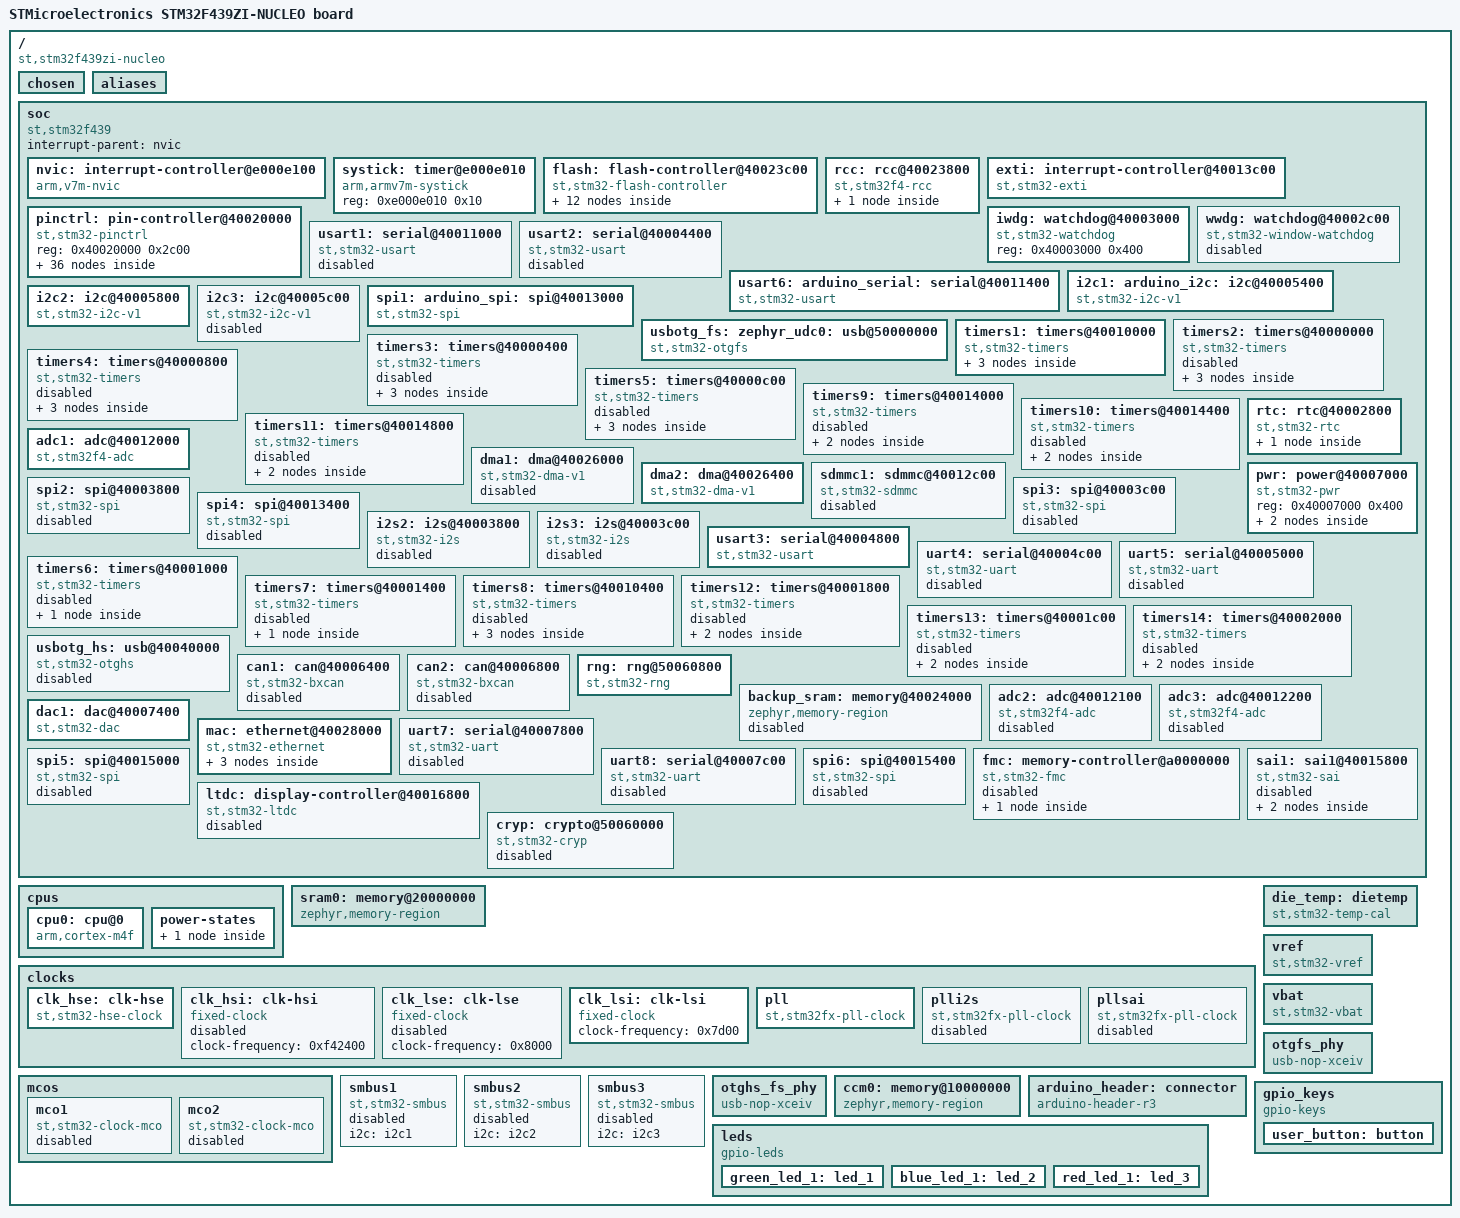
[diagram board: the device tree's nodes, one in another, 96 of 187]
/dts-v1/;

/* node '/' defined in zephyr/dts/common/skeleton.dtsi:9 */
/ {
	#address-cells = < 0x1 >;                              /* in zephyr/dts/common/skeleton.dtsi:10 */
	#size-cells = < 0x1 >;                                 /* in zephyr/dts/common/skeleton.dtsi:11 */
	model = "STMicroelectronics STM32F439ZI-NUCLEO board"; /* in zephyr/boards/st/nucleo_f439zi/nucleo_f439zi.dts:14 */
	compatible = "st,stm32f439zi-nucleo";                  /* in zephyr/boards/st/nucleo_f439zi/nucleo_f439zi.dts:15 */

	/* node '/chosen' defined in zephyr/dts/common/skeleton.dtsi:13 */
	chosen {
		zephyr,flash-controller = &flash;         /* in zephyr/dts/arm/st/f4/stm32f4.dtsi:26 */
		zephyr,system-timer-companion = &rtc;     /* in zephyr/dts/arm/st/f4/stm32f4.dtsi:27 */
		zephyr,entropy = &rng;                    /* in zephyr/dts/arm/st/f4/stm32f405.dtsi:13 */
		zephyr,sram = &sram0;                     /* in zephyr/boards/st/nucleo_f439zi/nucleo_f439zi.dts:20 */
		zephyr,flash = &flash0;                   /* in zephyr/boards/st/nucleo_f439zi/nucleo_f439zi.dts:21 */
		zephyr,dtcm = &ccm0;                      /* in zephyr/boards/st/nucleo_f439zi/nucleo_f439zi.dts:22 */
		zephyr,code-partition = &slot0_partition; /* in zephyr/boards/st/nucleo_f439zi/nucleo_f439zi.dts:23 */
		zephyr,shell-uart = &usart3;              /* in ../../../../development/germany/sm3/research/can_t1s_latency_bench/host-tools/demo/terminal_config/build/zephyr/boards/nucleo_f439zi.overlay:3 */
		zephyr,console = &usart3;                 /* in ../../../../development/germany/sm3/research/can_t1s_latency_bench/host-tools/demo/terminal_config/build/zephyr/boards/nucleo_f439zi.overlay:4 */
	};

	/* node '/aliases' defined in zephyr/dts/common/skeleton.dtsi:15 */
	aliases {
		led0 = &green_led_1;   /* in zephyr/boards/st/nucleo_f439zi/nucleo_f439zi.dts:56 */
		led1 = &blue_led_1;    /* in zephyr/boards/st/nucleo_f439zi/nucleo_f439zi.dts:57 */
		led2 = &red_led_1;     /* in zephyr/boards/st/nucleo_f439zi/nucleo_f439zi.dts:58 */
		sw0 = &user_button;    /* in zephyr/boards/st/nucleo_f439zi/nucleo_f439zi.dts:59 */
		watchdog0 = &iwdg;     /* in zephyr/boards/st/nucleo_f439zi/nucleo_f439zi.dts:60 */
		die-temp0 = &die_temp; /* in zephyr/boards/st/nucleo_f439zi/nucleo_f439zi.dts:61 */
		volt-sensor0 = &vref;  /* in zephyr/boards/st/nucleo_f439zi/nucleo_f439zi.dts:62 */
		volt-sensor1 = &vbat;  /* in zephyr/boards/st/nucleo_f439zi/nucleo_f439zi.dts:63 */
	};

	/* node '/soc' defined in zephyr/dts/arm/armv7-m.dtsi:6 */
	soc {
		#address-cells = < 0x1 >;     /* in zephyr/dts/arm/armv7-m.dtsi:7 */
		#size-cells = < 0x1 >;        /* in zephyr/dts/arm/armv7-m.dtsi:8 */
		interrupt-parent = < &nvic >; /* in zephyr/dts/arm/armv7-m.dtsi:10 */
		ranges;                       /* in zephyr/dts/arm/armv7-m.dtsi:11 */
		compatible = "st,stm32f439",
		             "st,stm32f4",
		             "simple-bus";    /* in zephyr/dts/arm/st/f4/stm32f439.dtsi:11 */

		/* node '/soc/interrupt-controller@e000e100' defined in zephyr/dts/arm/armv7-m.dtsi:13 */
		nvic: interrupt-controller@e000e100 {
			#address-cells = < 0x1 >;            /* in zephyr/dts/arm/armv7-m.dtsi:14 */
			compatible = "arm,v7m-nvic";         /* in zephyr/dts/arm/armv7-m.dtsi:15 */
			reg = < 0xe000e100 0xc00 >;          /* in zephyr/dts/arm/armv7-m.dtsi:16 */
			interrupt-controller;                /* in zephyr/dts/arm/armv7-m.dtsi:17 */
			#interrupt-cells = < 0x2 >;          /* in zephyr/dts/arm/armv7-m.dtsi:18 */
			arm,num-irq-priority-bits = < 0x4 >; /* in zephyr/dts/arm/st/f4/stm32f4.dtsi:733 */
			phandle = < 0x1 >;                   /* in zephyr/dts/arm/armv7-m.dtsi:10 */
		};

		/* node '/soc/timer@e000e010' defined in zephyr/dts/arm/armv7-m.dtsi:21 */
		systick: timer@e000e010 {
			compatible = "arm,armv7m-systick"; /* in zephyr/dts/arm/armv7-m.dtsi:22 */
			reg = < 0xe000e010 0x10 >;         /* in zephyr/dts/arm/armv7-m.dtsi:23 */
		};

		/* node '/soc/flash-controller@40023c00' defined in zephyr/dts/arm/st/f4/stm32f4.dtsi:112 */
		flash: flash-controller@40023c00 {
			compatible = "st,stm32-flash-controller",
			             "st,stm32f4-flash-controller"; /* in zephyr/dts/arm/st/f4/stm32f4.dtsi:113 */
			reg = < 0x40023c00 0x400 >;                 /* in zephyr/dts/arm/st/f4/stm32f4.dtsi:114 */
			interrupts = < 0x4 0x0 >;                   /* in zephyr/dts/arm/st/f4/stm32f4.dtsi:115 */
			#address-cells = < 0x1 >;                   /* in zephyr/dts/arm/st/f4/stm32f4.dtsi:117 */
			#size-cells = < 0x1 >;                      /* in zephyr/dts/arm/st/f4/stm32f4.dtsi:118 */
			ranges;                                     /* in zephyr/dts/arm/st/f4/stm32f4.dtsi:119 */

			/* node '/soc/flash-controller@40023c00/flash@8000000' defined in zephyr/dts/arm/st/f4/stm32f4.dtsi:121 */
			flash0: flash@8000000 {
				compatible = "st,stm32f4-nv-flash",
				             "st,stm32-nv-flash",
				             "soc-nv-flash";         /* in zephyr/dts/arm/st/f4/stm32f4.dtsi:122 */
				#address-cells = < 0x1 >;            /* in zephyr/dts/arm/st/f4/stm32f4.dtsi:124 */
				#size-cells = < 0x1 >;               /* in zephyr/dts/arm/st/f4/stm32f4.dtsi:125 */
				write-block-size = < 0x1 >;          /* in zephyr/dts/arm/st/f4/stm32f4.dtsi:126 */
				max-erase-time = < 0xfa0 >;          /* in zephyr/dts/arm/st/f4/stm32f4.dtsi:128 */
				reg = < 0x8000000 0x200000 >;        /* in zephyr/dts/arm/st/f4/stm32f439Xi.dtsi:23 */
				ranges = < 0x0 0x8000000 0x200000 >; /* in zephyr/dts/arm/st/f4/stm32f439Xi.dtsi:24 */

				/* node '/soc/flash-controller@40023c00/flash@8000000/partitions' defined in zephyr/boards/st/nucleo_f439zi/nucleo_f439zi.dts:212 */
				partitions {
					#address-cells = < 0x1 >; /* in zephyr/boards/st/nucleo_f439zi/nucleo_f439zi.dts:213 */
					#size-cells = < 0x1 >;    /* in zephyr/boards/st/nucleo_f439zi/nucleo_f439zi.dts:214 */
					ranges;                   /* in zephyr/boards/st/nucleo_f439zi/nucleo_f439zi.dts:215 */

					/* node '/soc/flash-controller@40023c00/flash@8000000/partitions/partition@0' defined in zephyr/boards/st/nucleo_f439zi/nucleo_f439zi.dts:218 */
					boot_partition: partition@0 {
						compatible = "zephyr,mapped-partition"; /* in zephyr/boards/st/nucleo_f439zi/nucleo_f439zi.dts:219 */
						label = "mcuboot";                      /* in zephyr/boards/st/nucleo_f439zi/nucleo_f439zi.dts:220 */
						reg = < 0x0 0x8000 >;                   /* in zephyr/boards/st/nucleo_f439zi/nucleo_f439zi.dts:221 */
						read-only;                              /* in zephyr/boards/st/nucleo_f439zi/nucleo_f439zi.dts:222 */
					};

					/* node '/soc/flash-controller@40023c00/flash@8000000/partitions/partition@20000' defined in zephyr/boards/st/nucleo_f439zi/nucleo_f439zi.dts:248 */
					slot0_partition: partition@20000 {
						compatible = "zephyr,mapped-partition"; /* in zephyr/boards/st/nucleo_f439zi/nucleo_f439zi.dts:249 */
						label = "image-0";                      /* in zephyr/boards/st/nucleo_f439zi/nucleo_f439zi.dts:250 */
						reg = < 0x20000 0xe0000 >;              /* in zephyr/boards/st/nucleo_f439zi/nucleo_f439zi.dts:251 */
					};

					/* node '/soc/flash-controller@40023c00/flash@8000000/partitions/partition@120000' defined in zephyr/boards/st/nucleo_f439zi/nucleo_f439zi.dts:264 */
					slot1_partition: partition@120000 {
						compatible = "zephyr,mapped-partition"; /* in zephyr/boards/st/nucleo_f439zi/nucleo_f439zi.dts:265 */
						label = "image-1";                      /* in zephyr/boards/st/nucleo_f439zi/nucleo_f439zi.dts:266 */
						reg = < 0x120000 0xc0000 >;             /* in zephyr/boards/st/nucleo_f439zi/nucleo_f439zi.dts:267 */
					};

					/* node '/soc/flash-controller@40023c00/flash@8000000/partitions/partition@8000' defined in ../../../../development/germany/sm3/research/can_t1s_latency_bench/host-tools/demo/terminal_config/build/zephyr/boards/nucleo_f439zi.overlay:16 */
					storage_partition: partition@8000 {
						compatible = "zephyr,mapped-partition"; /* in ../../../../development/germany/sm3/research/can_t1s_latency_bench/host-tools/demo/terminal_config/build/zephyr/boards/nucleo_f439zi.overlay:17 */
						label = "storage";                      /* in ../../../../development/germany/sm3/research/can_t1s_latency_bench/host-tools/demo/terminal_config/build/zephyr/boards/nucleo_f439zi.overlay:18 */
						reg = < 0x8000 0x8000 >;                /* in ../../../../development/germany/sm3/research/can_t1s_latency_bench/host-tools/demo/terminal_config/build/zephyr/boards/nucleo_f439zi.overlay:19 */
					};
				};
			};

			/* node '/soc/flash-controller@40023c00/flash@1fff7800' defined in zephyr/dts/arm/st/f4/stm32f4.dtsi:131 */
			st_nvm_user_otp: flash@1fff7800 {
				compatible = "st,stm32-nvm-otp"; /* in zephyr/dts/arm/st/f4/stm32f4.dtsi:132 */
				reg = < 0x1fff7800 0x200 >;      /* in zephyr/dts/arm/st/f4/stm32f4.dtsi:133 */
				status = "disabled";             /* in zephyr/dts/arm/st/f4/stm32f4.dtsi:134 */
			};

			/* node '/soc/flash-controller@40023c00/flash@1fff7a00' defined in zephyr/dts/arm/st/f4/stm32f4.dtsi:148 */
			flash@1fff7a00 {
				compatible = "st,stm32-nvm-otp"; /* in zephyr/dts/arm/st/f4/stm32f4.dtsi:149 */
				reg = < 0x1fff7a00 0x100 >;      /* in zephyr/dts/arm/st/f4/stm32f4.dtsi:150 */

				/* node '/soc/flash-controller@40023c00/flash@1fff7a00/nvmem-layout' defined in zephyr/dts/arm/st/f4/stm32f4.dtsi:152 */
				nvmem-layout {
					compatible = "fixed-layout"; /* in zephyr/dts/arm/st/f4/stm32f4.dtsi:153 */
					#address-cells = < 0x1 >;    /* in zephyr/dts/arm/st/f4/stm32f4.dtsi:154 */
					#size-cells = < 0x1 >;       /* in zephyr/dts/arm/st/f4/stm32f4.dtsi:155 */

					/* node '/soc/flash-controller@40023c00/flash@1fff7a00/nvmem-layout/vrefint@2a' defined in zephyr/dts/arm/st/f4/stm32f4.dtsi:157 */
					vrefint_otp: vrefint@2a {
						reg = < 0x2a 0x2 >;          /* in zephyr/dts/arm/st/f4/stm32f4.dtsi:158 */
						#nvmem-cell-cells = < 0x0 >; /* in zephyr/dts/arm/st/f4/stm32f4.dtsi:159 */
						read-only;                   /* in zephyr/dts/arm/st/f4/stm32f4.dtsi:160 */
						phandle = < 0x2b >;          /* in zephyr/dts/arm/st/f4/stm32f4.dtsi:689 */
					};

					/* node '/soc/flash-controller@40023c00/flash@1fff7a00/nvmem-layout/ts-cal1@2c' defined in zephyr/dts/arm/st/f4/stm32f4.dtsi:163 */
					ts_cal1_otp: ts-cal1@2c {
						reg = < 0x2c 0x2 >;          /* in zephyr/dts/arm/st/f4/stm32f4.dtsi:164 */
						#nvmem-cell-cells = < 0x0 >; /* in zephyr/dts/arm/st/f4/stm32f4.dtsi:165 */
						read-only;                   /* in zephyr/dts/arm/st/f4/stm32f4.dtsi:166 */
						phandle = < 0x28 >;          /* in zephyr/dts/arm/st/f4/stm32f4.dtsi:678 */
					};

					/* node '/soc/flash-controller@40023c00/flash@1fff7a00/nvmem-layout/ts-cal2@2e' defined in zephyr/dts/arm/st/f4/stm32f4.dtsi:169 */
					ts_cal2_otp: ts-cal2@2e {
						reg = < 0x2e 0x2 >;          /* in zephyr/dts/arm/st/f4/stm32f4.dtsi:170 */
						#nvmem-cell-cells = < 0x0 >; /* in zephyr/dts/arm/st/f4/stm32f4.dtsi:171 */
						read-only;                   /* in zephyr/dts/arm/st/f4/stm32f4.dtsi:172 */
						phandle = < 0x29 >;          /* in zephyr/dts/arm/st/f4/stm32f4.dtsi:678 */
					};
				};
			};
		};

		/* node '/soc/rcc@40023800' defined in zephyr/dts/arm/st/f4/stm32f4.dtsi:178 */
		rcc: rcc@40023800 {
			#clock-cells = < 0x2 >;          /* in zephyr/dts/arm/st/f4/stm32f4.dtsi:180 */
			reg = < 0x40023800 0x400 >;      /* in zephyr/dts/arm/st/f4/stm32f4.dtsi:181 */
			compatible = "st,stm32f4-rcc";   /* in zephyr/dts/arm/st/f4/stm32f427.dtsi:25 */
			clocks = < &pll >;               /* in zephyr/boards/st/nucleo_f439zi/nucleo_f439zi.dts:87 */
			clock-frequency = < 0xa037a00 >; /* in zephyr/boards/st/nucleo_f439zi/nucleo_f439zi.dts:88 */
			ahb-prescaler = < 0x1 >;         /* in zephyr/boards/st/nucleo_f439zi/nucleo_f439zi.dts:89 */
			apb1-prescaler = < 0x4 >;        /* in zephyr/boards/st/nucleo_f439zi/nucleo_f439zi.dts:90 */
			apb2-prescaler = < 0x2 >;        /* in zephyr/boards/st/nucleo_f439zi/nucleo_f439zi.dts:91 */
			phandle = < 0x3 >;               /* in zephyr/dts/arm/st/f4/stm32f4.dtsi:195 */

			/* node '/soc/rcc@40023800/reset-controller' defined in zephyr/dts/arm/st/f4/stm32f4.dtsi:183 */
			rctl: reset-controller {
				compatible = "st,stm32-rcc-rctl"; /* in zephyr/dts/arm/st/f4/stm32f4.dtsi:184 */
				#reset-cells = < 0x1 >;           /* in zephyr/dts/arm/st/f4/stm32f4.dtsi:185 */
				phandle = < 0x4 >;                /* in zephyr/dts/arm/st/f4/stm32f4.dtsi:295 */
			};
		};

		/* node '/soc/interrupt-controller@40013c00' defined in zephyr/dts/arm/st/f4/stm32f4.dtsi:189 */
		exti: interrupt-controller@40013c00 {
			compatible = "st,stm32-exti";  /* in zephyr/dts/arm/st/f4/stm32f4.dtsi:190 */
			interrupt-controller;          /* in zephyr/dts/arm/st/f4/stm32f4.dtsi:191 */
			#interrupt-cells = < 0x1 >;    /* in zephyr/dts/arm/st/f4/stm32f4.dtsi:192 */
			#address-cells = < 0x0 >;      /* in zephyr/dts/arm/st/f4/stm32f4.dtsi:193 */
			reg = < 0x40013c00 0x400 >;    /* in zephyr/dts/arm/st/f4/stm32f4.dtsi:194 */
			clocks = < &rcc 0x44 0x4000 >; /* in zephyr/dts/arm/st/f4/stm32f4.dtsi:195 */
			num-lines = < 0x20 >;          /* in zephyr/dts/arm/st/f4/stm32f4.dtsi:196 */
			interrupts = < 0x6 0x0 >,
			             < 0x7 0x0 >,
			             < 0x8 0x0 >,
			             < 0x9 0x0 >,
			             < 0xa 0x0 >,
			             < 0x17 0x0 >,
			             < 0x28 0x0 >;     /* in zephyr/dts/arm/st/f4/stm32f4.dtsi:197 */
			interrupt-names = "line0",
			                  "line1",
			                  "line2",
			                  "line3",
			                  "line4",
			                  "line5-9",
			                  "line10-15"; /* in zephyr/dts/arm/st/f4/stm32f4.dtsi:199 */
			line-ranges = < 0x0 0x1 >,
			              < 0x1 0x1 >,
			              < 0x2 0x1 >,
			              < 0x3 0x1 >,
			              < 0x4 0x1 >,
			              < 0x5 0x5 >,
			              < 0xa 0x6 >;     /* in zephyr/dts/arm/st/f4/stm32f4.dtsi:201 */
		};

		/* node '/soc/pin-controller@40020000' defined in zephyr/dts/arm/st/f4/stm32f4.dtsi:205 */
		pinctrl: pin-controller@40020000 {
			compatible = "st,stm32-pinctrl"; /* in zephyr/dts/arm/st/f4/stm32f4.dtsi:206 */
			#address-cells = < 0x1 >;        /* in zephyr/dts/arm/st/f4/stm32f4.dtsi:207 */
			#size-cells = < 0x1 >;           /* in zephyr/dts/arm/st/f4/stm32f4.dtsi:208 */
			ranges;                          /* in zephyr/dts/arm/st/f4/stm32f4.dtsi:210 */
			reg = < 0x40020000 0x2c00 >;     /* in zephyr/dts/arm/st/f4/stm32f427.dtsi:29 */

			/* node '/soc/pin-controller@40020000/gpio@40020000' defined in zephyr/dts/arm/st/f4/stm32f4.dtsi:212 */
			gpioa: gpio@40020000 {
				compatible = "st,stm32-gpio"; /* in zephyr/dts/arm/st/f4/stm32f4.dtsi:213 */
				gpio-controller;              /* in zephyr/dts/arm/st/f4/stm32f4.dtsi:214 */
				#gpio-cells = < 0x2 >;        /* in zephyr/dts/arm/st/f4/stm32f4.dtsi:215 */
				reg = < 0x40020000 0x400 >;   /* in zephyr/dts/arm/st/f4/stm32f4.dtsi:216 */
				clocks = < &rcc 0x30 0x1 >;   /* in zephyr/dts/arm/st/f4/stm32f4.dtsi:217 */
				phandle = < 0x15 >;           /* in zephyr/dts/arm/st/f4/stm32f4.dtsi:670 */
			};

			/* node '/soc/pin-controller@40020000/gpio@40020400' defined in zephyr/dts/arm/st/f4/stm32f4.dtsi:220 */
			gpiob: gpio@40020400 {
				compatible = "st,stm32-gpio"; /* in zephyr/dts/arm/st/f4/stm32f4.dtsi:221 */
				gpio-controller;              /* in zephyr/dts/arm/st/f4/stm32f4.dtsi:222 */
				#gpio-cells = < 0x2 >;        /* in zephyr/dts/arm/st/f4/stm32f4.dtsi:223 */
				reg = < 0x40020400 0x400 >;   /* in zephyr/dts/arm/st/f4/stm32f4.dtsi:224 */
				clocks = < &rcc 0x30 0x2 >;   /* in zephyr/dts/arm/st/f4/stm32f4.dtsi:225 */
				phandle = < 0x9 >;            /* in zephyr/boards/st/nucleo_f439zi/nucleo_f439zi.dts:115 */
			};

			/* node '/soc/pin-controller@40020000/gpio@40020800' defined in zephyr/dts/arm/st/f4/stm32f4.dtsi:228 */
			gpioc: gpio@40020800 {
				compatible = "st,stm32-gpio"; /* in zephyr/dts/arm/st/f4/stm32f4.dtsi:229 */
				gpio-controller;              /* in zephyr/dts/arm/st/f4/stm32f4.dtsi:230 */
				#gpio-cells = < 0x2 >;        /* in zephyr/dts/arm/st/f4/stm32f4.dtsi:231 */
				reg = < 0x40020800 0x400 >;   /* in zephyr/dts/arm/st/f4/stm32f4.dtsi:232 */
				clocks = < &rcc 0x30 0x4 >;   /* in zephyr/dts/arm/st/f4/stm32f4.dtsi:233 */
				phandle = < 0x2f >;           /* in zephyr/boards/st/nucleo_f439zi/arduino_r3_connector.dtsi:15 */
			};

			/* node '/soc/pin-controller@40020000/gpio@40020c00' defined in zephyr/dts/arm/st/f4/stm32f4.dtsi:236 */
			gpiod: gpio@40020c00 {
				compatible = "st,stm32-gpio"; /* in zephyr/dts/arm/st/f4/stm32f4.dtsi:237 */
				gpio-controller;              /* in zephyr/dts/arm/st/f4/stm32f4.dtsi:238 */
				#gpio-cells = < 0x2 >;        /* in zephyr/dts/arm/st/f4/stm32f4.dtsi:239 */
				reg = < 0x40020c00 0x400 >;   /* in zephyr/dts/arm/st/f4/stm32f4.dtsi:240 */
				clocks = < &rcc 0x30 0x8 >;   /* in zephyr/dts/arm/st/f4/stm32f4.dtsi:241 */
				phandle = < 0xf >;            /* in zephyr/boards/st/nucleo_f439zi/nucleo_f439zi.dts:133 */
			};

			/* node '/soc/pin-controller@40020000/gpio@40021000' defined in zephyr/dts/arm/st/f4/stm32f4.dtsi:244 */
			gpioe: gpio@40021000 {
				compatible = "st,stm32-gpio"; /* in zephyr/dts/arm/st/f4/stm32f4.dtsi:245 */
				gpio-controller;              /* in zephyr/dts/arm/st/f4/stm32f4.dtsi:246 */
				#gpio-cells = < 0x2 >;        /* in zephyr/dts/arm/st/f4/stm32f4.dtsi:247 */
				reg = < 0x40021000 0x400 >;   /* in zephyr/dts/arm/st/f4/stm32f4.dtsi:248 */
				clocks = < &rcc 0x30 0x10 >;  /* in zephyr/dts/arm/st/f4/stm32f4.dtsi:249 */
				phandle = < 0x32 >;           /* in zephyr/boards/st/nucleo_f439zi/arduino_r3_connector.dtsi:15 */
			};

			/* node '/soc/pin-controller@40020000/gpio@40021400' defined in zephyr/dts/arm/st/f4/stm32f4.dtsi:252 */
			gpiof: gpio@40021400 {
				compatible = "st,stm32-gpio"; /* in zephyr/dts/arm/st/f4/stm32f405.dtsi:27 */
				gpio-controller;              /* in zephyr/dts/arm/st/f4/stm32f405.dtsi:28 */
				#gpio-cells = < 0x2 >;        /* in zephyr/dts/arm/st/f4/stm32f405.dtsi:29 */
				reg = < 0x40021400 0x400 >;   /* in zephyr/dts/arm/st/f4/stm32f405.dtsi:30 */
				clocks = < &rcc 0x30 0x20 >;  /* in zephyr/dts/arm/st/f4/stm32f405.dtsi:31 */
				phandle = < 0x30 >;           /* in zephyr/boards/st/nucleo_f439zi/arduino_r3_connector.dtsi:15 */
			};

			/* node '/soc/pin-controller@40020000/gpio@40021800' defined in zephyr/dts/arm/st/f4/stm32f4.dtsi:260 */
			gpiog: gpio@40021800 {
				compatible = "st,stm32-gpio"; /* in zephyr/dts/arm/st/f4/stm32f405.dtsi:35 */
				gpio-controller;              /* in zephyr/dts/arm/st/f4/stm32f405.dtsi:36 */
				#gpio-cells = < 0x2 >;        /* in zephyr/dts/arm/st/f4/stm32f405.dtsi:37 */
				reg = < 0x40021800 0x400 >;   /* in zephyr/dts/arm/st/f4/stm32f405.dtsi:38 */
				clocks = < &rcc 0x30 0x40 >;  /* in zephyr/dts/arm/st/f4/stm32f405.dtsi:39 */
				phandle = < 0x31 >;           /* in zephyr/boards/st/nucleo_f439zi/arduino_r3_connector.dtsi:15 */
			};

			/* node '/soc/pin-controller@40020000/gpio@40021c00' defined in zephyr/dts/arm/st/f4/stm32f4.dtsi:268 */
			gpioh: gpio@40021c00 {
				compatible = "st,stm32-gpio"; /* in zephyr/dts/arm/st/f4/stm32f4.dtsi:269 */
				gpio-controller;              /* in zephyr/dts/arm/st/f4/stm32f4.dtsi:270 */
				#gpio-cells = < 0x2 >;        /* in zephyr/dts/arm/st/f4/stm32f4.dtsi:271 */
				reg = < 0x40021c00 0x400 >;   /* in zephyr/dts/arm/st/f4/stm32f4.dtsi:272 */
				clocks = < &rcc 0x30 0x80 >;  /* in zephyr/dts/arm/st/f4/stm32f4.dtsi:273 */
			};

			/* node '/soc/pin-controller@40020000/gpio@40022000' defined in zephyr/dts/arm/st/f4/stm32f405.dtsi:42 */
			gpioi: gpio@40022000 {
				compatible = "st,stm32-gpio"; /* in zephyr/dts/arm/st/f4/stm32f405.dtsi:43 */
				gpio-controller;              /* in zephyr/dts/arm/st/f4/stm32f405.dtsi:44 */
				#gpio-cells = < 0x2 >;        /* in zephyr/dts/arm/st/f4/stm32f405.dtsi:45 */
				reg = < 0x40022000 0x400 >;   /* in zephyr/dts/arm/st/f4/stm32f405.dtsi:46 */
				clocks = < &rcc 0x30 0x100 >; /* in zephyr/dts/arm/st/f4/stm32f405.dtsi:47 */
			};

			/* node '/soc/pin-controller@40020000/gpio@40022400' defined in zephyr/dts/arm/st/f4/stm32f427.dtsi:31 */
			gpioj: gpio@40022400 {
				compatible = "st,stm32-gpio"; /* in zephyr/dts/arm/st/f4/stm32f427.dtsi:32 */
				gpio-controller;              /* in zephyr/dts/arm/st/f4/stm32f427.dtsi:33 */
				#gpio-cells = < 0x2 >;        /* in zephyr/dts/arm/st/f4/stm32f427.dtsi:34 */
				reg = < 0x40022400 0x400 >;   /* in zephyr/dts/arm/st/f4/stm32f427.dtsi:35 */
				clocks = < &rcc 0x30 0x200 >; /* in zephyr/dts/arm/st/f4/stm32f427.dtsi:36 */
			};

			/* node '/soc/pin-controller@40020000/gpio@40022800' defined in zephyr/dts/arm/st/f4/stm32f427.dtsi:39 */
			gpiok: gpio@40022800 {
				compatible = "st,stm32-gpio"; /* in zephyr/dts/arm/st/f4/stm32f427.dtsi:40 */
				gpio-controller;              /* in zephyr/dts/arm/st/f4/stm32f427.dtsi:41 */
				#gpio-cells = < 0x2 >;        /* in zephyr/dts/arm/st/f4/stm32f427.dtsi:42 */
				reg = < 0x40022800 0x400 >;   /* in zephyr/dts/arm/st/f4/stm32f427.dtsi:43 */
				clocks = < &rcc 0x30 0x400 >; /* in zephyr/dts/arm/st/f4/stm32f427.dtsi:44 */
			};

			/* node '/soc/pin-controller@40020000/adc1_in0_pa0' defined in modules/hal/stm32/dts/st/f4/stm32f439z(g-i)tx-pinctrl.dtsi:11 */
			adc1_in0_pa0: adc1_in0_pa0 {
				pinmux = < 0x10 >;  /* in modules/hal/stm32/dts/st/f4/stm32f439z(g-i)tx-pinctrl.dtsi:12 */
				phandle = < 0x14 >; /* in zephyr/boards/st/nucleo_f439zi/nucleo_f439zi.dts:95 */
			};

			/* node '/soc/pin-controller@40020000/dac_out1_pa4' defined in modules/hal/stm32/dts/st/f4/stm32f439z(g-i)tx-pinctrl.dtsi:708 */
			dac_out1_pa4: dac_out1_pa4 {
				pinmux = < 0x90 >;  /* in modules/hal/stm32/dts/st/f4/stm32f439z(g-i)tx-pinctrl.dtsi:709 */
				phandle = < 0x1a >; /* in zephyr/boards/st/nucleo_f439zi/nucleo_f439zi.dts:108 */
			};

			/* node '/soc/pin-controller@40020000/eth_ref_clk_pa1' defined in modules/hal/stm32/dts/st/f4/stm32f439z(g-i)tx-pinctrl.dtsi:883 */
			eth_ref_clk_pa1: eth_ref_clk_pa1 {
				pinmux = < 0x2b >;             /* in modules/hal/stm32/dts/st/f4/stm32f439z(g-i)tx-pinctrl.dtsi:884 */
				slew-rate = "very-high-speed"; /* in modules/hal/stm32/dts/st/f4/stm32f439z(g-i)tx-pinctrl.dtsi:885 */
				phandle = < 0x1d >;            /* in zephyr/boards/st/nucleo_f439zi/nucleo_f439zi.dts:188 */
			};

			/* node '/soc/pin-controller@40020000/eth_mdio_pa2' defined in modules/hal/stm32/dts/st/f4/stm32f439z(g-i)tx-pinctrl.dtsi:893 */
			eth_mdio_pa2: eth_mdio_pa2 {
				pinmux = < 0x4b >;             /* in modules/hal/stm32/dts/st/f4/stm32f439z(g-i)tx-pinctrl.dtsi:894 */
				slew-rate = "very-high-speed"; /* in modules/hal/stm32/dts/st/f4/stm32f439z(g-i)tx-pinctrl.dtsi:895 */
				phandle = < 0x23 >;            /* in zephyr/boards/st/nucleo_f439zi/nucleo_f439zi.dts:202 */
			};

			/* node '/soc/pin-controller@40020000/eth_crs_dv_pa7' defined in modules/hal/stm32/dts/st/f4/stm32f439z(g-i)tx-pinctrl.dtsi:903 */
			eth_crs_dv_pa7: eth_crs_dv_pa7 {
				pinmux = < 0xeb >;             /* in modules/hal/stm32/dts/st/f4/stm32f439z(g-i)tx-pinctrl.dtsi:904 */
				slew-rate = "very-high-speed"; /* in modules/hal/stm32/dts/st/f4/stm32f439z(g-i)tx-pinctrl.dtsi:905 */
				phandle = < 0x1e >;            /* in zephyr/boards/st/nucleo_f439zi/nucleo_f439zi.dts:188 */
			};

			/* node '/soc/pin-controller@40020000/eth_txd1_pb13' defined in modules/hal/stm32/dts/st/f4/stm32f439z(g-i)tx-pinctrl.dtsi:948 */
			eth_txd1_pb13: eth_txd1_pb13 {
				pinmux = < 0x3ab >;            /* in modules/hal/stm32/dts/st/f4/stm32f439z(g-i)tx-pinctrl.dtsi:949 */
				slew-rate = "very-high-speed"; /* in modules/hal/stm32/dts/st/f4/stm32f439z(g-i)tx-pinctrl.dtsi:950 */
				phandle = < 0x21 >;            /* in zephyr/boards/st/nucleo_f439zi/nucleo_f439zi.dts:188 */
			};

			/* node '/soc/pin-controller@40020000/eth_mdc_pc1' defined in modules/hal/stm32/dts/st/f4/stm32f439z(g-i)tx-pinctrl.dtsi:953 */
			eth_mdc_pc1: eth_mdc_pc1 {
				pinmux = < 0x42b >;            /* in modules/hal/stm32/dts/st/f4/stm32f439z(g-i)tx-pinctrl.dtsi:954 */
				slew-rate = "very-high-speed"; /* in modules/hal/stm32/dts/st/f4/stm32f439z(g-i)tx-pinctrl.dtsi:955 */
				phandle = < 0x24 >;            /* in zephyr/boards/st/nucleo_f439zi/nucleo_f439zi.dts:202 */
			};

			/* node '/soc/pin-controller@40020000/eth_rxd0_pc4' defined in modules/hal/stm32/dts/st/f4/stm32f439z(g-i)tx-pinctrl.dtsi:968 */
			eth_rxd0_pc4: eth_rxd0_pc4 {
				pinmux = < 0x48b >;            /* in modules/hal/stm32/dts/st/f4/stm32f439z(g-i)tx-pinctrl.dtsi:969 */
				slew-rate = "very-high-speed"; /* in modules/hal/stm32/dts/st/f4/stm32f439z(g-i)tx-pinctrl.dtsi:970 */
				phandle = < 0x1b >;            /* in zephyr/boards/st/nucleo_f439zi/nucleo_f439zi.dts:188 */
			};

			/* node '/soc/pin-controller@40020000/eth_rxd1_pc5' defined in modules/hal/stm32/dts/st/f4/stm32f439z(g-i)tx-pinctrl.dtsi:973 */
			eth_rxd1_pc5: eth_rxd1_pc5 {
				pinmux = < 0x4ab >;            /* in modules/hal/stm32/dts/st/f4/stm32f439z(g-i)tx-pinctrl.dtsi:974 */
				slew-rate = "very-high-speed"; /* in modules/hal/stm32/dts/st/f4/stm32f439z(g-i)tx-pinctrl.dtsi:975 */
				phandle = < 0x1c >;            /* in zephyr/boards/st/nucleo_f439zi/nucleo_f439zi.dts:188 */
			};

			/* node '/soc/pin-controller@40020000/eth_tx_en_pg11' defined in modules/hal/stm32/dts/st/f4/stm32f439z(g-i)tx-pinctrl.dtsi:988 */
			eth_tx_en_pg11: eth_tx_en_pg11 {
				pinmux = < 0xd6b >;            /* in modules/hal/stm32/dts/st/f4/stm32f439z(g-i)tx-pinctrl.dtsi:989 */
				slew-rate = "very-high-speed"; /* in modules/hal/stm32/dts/st/f4/stm32f439z(g-i)tx-pinctrl.dtsi:990 */
				phandle = < 0x1f >;            /* in zephyr/boards/st/nucleo_f439zi/nucleo_f439zi.dts:188 */
			};

			/* node '/soc/pin-controller@40020000/eth_txd0_pg13' defined in modules/hal/stm32/dts/st/f4/stm32f439z(g-i)tx-pinctrl.dtsi:993 */
			eth_txd0_pg13: eth_txd0_pg13 {
				pinmux = < 0xdab >;            /* in modules/hal/stm32/dts/st/f4/stm32f439z(g-i)tx-pinctrl.dtsi:994 */
				slew-rate = "very-high-speed"; /* in modules/hal/stm32/dts/st/f4/stm32f439z(g-i)tx-pinctrl.dtsi:995 */
				phandle = < 0x20 >;            /* in zephyr/boards/st/nucleo_f439zi/nucleo_f439zi.dts:188 */
			};

			/* node '/soc/pin-controller@40020000/i2c1_scl_pb8' defined in modules/hal/stm32/dts/st/f4/stm32f439z(g-i)tx-pinctrl.dtsi:1389 */
			i2c1_scl_pb8: i2c1_scl_pb8 {
				pinmux = < 0x304 >; /* in modules/hal/stm32/dts/st/f4/stm32f439z(g-i)tx-pinctrl.dtsi:1390 */
				bias-pull-up;       /* in modules/hal/stm32/dts/st/f4/stm32f439z(g-i)tx-pinctrl.dtsi:1391 */
				drive-open-drain;   /* in modules/hal/stm32/dts/st/f4/stm32f439z(g-i)tx-pinctrl.dtsi:1392 */
				phandle = < 0x7 >;  /* in zephyr/boards/st/nucleo_f439zi/nucleo_f439zi.dts:113 */
			};

			/* node '/soc/pin-controller@40020000/i2c2_scl_pb10' defined in modules/hal/stm32/dts/st/f4/stm32f439z(g-i)tx-pinctrl.dtsi:1395 */
			i2c2_scl_pb10: i2c2_scl_pb10 {
				pinmux = < 0x344 >; /* in modules/hal/stm32/dts/st/f4/stm32f439z(g-i)tx-pinctrl.dtsi:1396 */
				bias-pull-up;       /* in modules/hal/stm32/dts/st/f4/stm32f439z(g-i)tx-pinctrl.dtsi:1397 */
				drive-open-drain;   /* in modules/hal/stm32/dts/st/f4/stm32f439z(g-i)tx-pinctrl.dtsi:1398 */
				phandle = < 0xa >;  /* in zephyr/boards/st/nucleo_f439zi/nucleo_f439zi.dts:122 */
			};

			/* node '/soc/pin-controller@40020000/i2c1_sda_pb9' defined in modules/hal/stm32/dts/st/f4/stm32f439z(g-i)tx-pinctrl.dtsi:1420 */
			i2c1_sda_pb9: i2c1_sda_pb9 {
				pinmux = < 0x324 >; /* in modules/hal/stm32/dts/st/f4/stm32f439z(g-i)tx-pinctrl.dtsi:1421 */
				bias-pull-up;       /* in modules/hal/stm32/dts/st/f4/stm32f439z(g-i)tx-pinctrl.dtsi:1422 */
				drive-open-drain;   /* in modules/hal/stm32/dts/st/f4/stm32f439z(g-i)tx-pinctrl.dtsi:1423 */
				phandle = < 0x8 >;  /* in zephyr/boards/st/nucleo_f439zi/nucleo_f439zi.dts:113 */
			};

			/* node '/soc/pin-controller@40020000/i2c2_sda_pb11' defined in modules/hal/stm32/dts/st/f4/stm32f439z(g-i)tx-pinctrl.dtsi:1426 */
			i2c2_sda_pb11: i2c2_sda_pb11 {
				pinmux = < 0x364 >; /* in modules/hal/stm32/dts/st/f4/stm32f439z(g-i)tx-pinctrl.dtsi:1427 */
				bias-pull-up;       /* in modules/hal/stm32/dts/st/f4/stm32f439z(g-i)tx-pinctrl.dtsi:1428 */
				drive-open-drain;   /* in modules/hal/stm32/dts/st/f4/stm32f439z(g-i)tx-pinctrl.dtsi:1429 */
				phandle = < 0xb >;  /* in zephyr/boards/st/nucleo_f439zi/nucleo_f439zi.dts:122 */
			};

			/* node '/soc/pin-controller@40020000/spi1_miso_pa6' defined in modules/hal/stm32/dts/st/f4/stm32f439z(g-i)tx-pinctrl.dtsi:1832 */
			spi1_miso_pa6: spi1_miso_pa6 {
				pinmux = < 0xc5 >;             /* in modules/hal/stm32/dts/st/f4/stm32f439z(g-i)tx-pinctrl.dtsi:1833 */
				bias-pull-down;                /* in modules/hal/stm32/dts/st/f4/stm32f439z(g-i)tx-pinctrl.dtsi:1834 */
				slew-rate = "very-high-speed"; /* in modules/hal/stm32/dts/st/f4/stm32f439z(g-i)tx-pinctrl.dtsi:1835 */
				phandle = < 0xd >;             /* in zephyr/boards/st/nucleo_f439zi/nucleo_f439zi.dts:131 */
			};

			/* node '/soc/pin-controller@40020000/spi1_mosi_pa7' defined in modules/hal/stm32/dts/st/f4/stm32f439z(g-i)tx-pinctrl.dtsi:1893 */
			spi1_mosi_pa7: spi1_mosi_pa7 {
				pinmux = < 0xe5 >;             /* in modules/hal/stm32/dts/st/f4/stm32f439z(g-i)tx-pinctrl.dtsi:1894 */
				bias-pull-down;                /* in modules/hal/stm32/dts/st/f4/stm32f439z(g-i)tx-pinctrl.dtsi:1895 */
				slew-rate = "very-high-speed"; /* in modules/hal/stm32/dts/st/f4/stm32f439z(g-i)tx-pinctrl.dtsi:1896 */
				phandle = < 0xe >;             /* in zephyr/boards/st/nucleo_f439zi/nucleo_f439zi.dts:131 */
			};

			/* node '/soc/pin-controller@40020000/spi1_sck_pa5' defined in modules/hal/stm32/dts/st/f4/stm32f439z(g-i)tx-pinctrl.dtsi:2027 */
			spi1_sck_pa5: spi1_sck_pa5 {
				pinmux = < 0xa5 >;             /* in modules/hal/stm32/dts/st/f4/stm32f439z(g-i)tx-pinctrl.dtsi:2028 */
				bias-pull-down;                /* in modules/hal/stm32/dts/st/f4/stm32f439z(g-i)tx-pinctrl.dtsi:2029 */
				slew-rate = "very-high-speed"; /* in modules/hal/stm32/dts/st/f4/stm32f439z(g-i)tx-pinctrl.dtsi:2030 */
				phandle = < 0xc >;             /* in zephyr/boards/st/nucleo_f439zi/nucleo_f439zi.dts:131 */
			};

			/* node '/soc/pin-controller@40020000/tim1_ch3_pe13' defined in modules/hal/stm32/dts/st/f4/stm32f439z(g-i)tx-pinctrl.dtsi:2183 */
			tim1_ch3_pe13: tim1_ch3_pe13 {
				pinmux = < 0x9a1 >; /* in modules/hal/stm32/dts/st/f4/stm32f439z(g-i)tx-pinctrl.dtsi:2184 */
				phandle = < 0x13 >; /* in zephyr/boards/st/nucleo_f439zi/nucleo_f439zi.dts:163 */
			};

			/* node '/soc/pin-controller@40020000/usart3_rx_pd9' defined in modules/hal/stm32/dts/st/f4/stm32f439z(g-i)tx-pinctrl.dtsi:2496 */
			usart3_rx_pd9: usart3_rx_pd9 {
				pinmux = < 0x727 >; /* in modules/hal/stm32/dts/st/f4/stm32f439z(g-i)tx-pinctrl.dtsi:2497 */
				phandle = < 0x18 >; /* in zephyr/boards/st/nucleo_f439zi/nucleo_f439zi.dts:138 */
			};

			/* node '/soc/pin-controller@40020000/usart6_rx_pg9' defined in modules/hal/stm32/dts/st/f4/stm32f439z(g-i)tx-pinctrl.dtsi:2516 */
			usart6_rx_pg9: usart6_rx_pg9 {
				pinmux = < 0xd28 >; /* in modules/hal/stm32/dts/st/f4/stm32f439z(g-i)tx-pinctrl.dtsi:2517 */
				phandle = < 0x6 >;  /* in zephyr/boards/st/nucleo_f439zi/nucleo_f439zi.dts:145 */
			};

			/* node '/soc/pin-controller@40020000/usart3_tx_pd8' defined in modules/hal/stm32/dts/st/f4/stm32f439z(g-i)tx-pinctrl.dtsi:2563 */
			usart3_tx_pd8: usart3_tx_pd8 {
				pinmux = < 0x707 >; /* in modules/hal/stm32/dts/st/f4/stm32f439z(g-i)tx-pinctrl.dtsi:2564 */
				bias-pull-up;       /* in modules/hal/stm32/dts/st/f4/stm32f439z(g-i)tx-pinctrl.dtsi:2565 */
				phandle = < 0x17 >; /* in zephyr/boards/st/nucleo_f439zi/nucleo_f439zi.dts:138 */
			};

			/* node '/soc/pin-controller@40020000/usart6_tx_pg14' defined in modules/hal/stm32/dts/st/f4/stm32f439z(g-i)tx-pinctrl.dtsi:2588 */
			usart6_tx_pg14: usart6_tx_pg14 {
				pinmux = < 0xdc8 >; /* in modules/hal/stm32/dts/st/f4/stm32f439z(g-i)tx-pinctrl.dtsi:2589 */
				bias-pull-up;       /* in modules/hal/stm32/dts/st/f4/stm32f439z(g-i)tx-pinctrl.dtsi:2590 */
				phandle = < 0x5 >;  /* in zephyr/boards/st/nucleo_f439zi/nucleo_f439zi.dts:145 */
			};

			/* node '/soc/pin-controller@40020000/usb_otg_fs_dm_pa11' defined in modules/hal/stm32/dts/st/f4/stm32f439z(g-i)tx-pinctrl.dtsi:2621 */
			usb_otg_fs_dm_pa11: usb_otg_fs_dm_pa11 {
				pinmux = < 0x16a >; /* in modules/hal/stm32/dts/st/f4/stm32f439z(g-i)tx-pinctrl.dtsi:2622 */
				phandle = < 0x11 >; /* in zephyr/boards/st/nucleo_f439zi/nucleo_f439zi.dts:152 */
			};

			/* node '/soc/pin-controller@40020000/usb_otg_fs_dp_pa12' defined in modules/hal/stm32/dts/st/f4/stm32f439z(g-i)tx-pinctrl.dtsi:2625 */
			usb_otg_fs_dp_pa12: usb_otg_fs_dp_pa12 {
				pinmux = < 0x18a >; /* in modules/hal/stm32/dts/st/f4/stm32f439z(g-i)tx-pinctrl.dtsi:2626 */
				phandle = < 0x12 >; /* in zephyr/boards/st/nucleo_f439zi/nucleo_f439zi.dts:152 */
			};
		};

		/* node '/soc/watchdog@40003000' defined in zephyr/dts/arm/st/f4/stm32f4.dtsi:277 */
		iwdg: watchdog@40003000 {
			compatible = "st,stm32-watchdog"; /* in zephyr/dts/arm/st/f4/stm32f4.dtsi:278 */
			reg = < 0x40003000 0x400 >;       /* in zephyr/dts/arm/st/f4/stm32f4.dtsi:279 */
			status = "okay";                  /* in zephyr/boards/st/nucleo_f439zi/nucleo_f439zi.dts:175 */
		};

		/* node '/soc/watchdog@40002c00' defined in zephyr/dts/arm/st/f4/stm32f4.dtsi:283 */
		wwdg: watchdog@40002c00 {
			compatible = "st,stm32-window-watchdog"; /* in zephyr/dts/arm/st/f4/stm32f4.dtsi:284 */
			reg = < 0x40002c00 0x400 >;              /* in zephyr/dts/arm/st/f4/stm32f4.dtsi:285 */
			clocks = < &rcc 0x40 0x800 >;            /* in zephyr/dts/arm/st/f4/stm32f4.dtsi:286 */
			interrupts = < 0x0 0x0 >;                /* in zephyr/dts/arm/st/f4/stm32f4.dtsi:287 */
			status = "disabled";                     /* in zephyr/dts/arm/st/f4/stm32f4.dtsi:288 */
		};

		/* node '/soc/serial@40011000' defined in zephyr/dts/arm/st/f4/stm32f4.dtsi:291 */
		usart1: serial@40011000 {
			compatible = "st,stm32-usart",
			             "st,stm32-uart";  /* in zephyr/dts/arm/st/f4/stm32f4.dtsi:292 */
			reg = < 0x40011000 0x400 >;    /* in zephyr/dts/arm/st/f4/stm32f4.dtsi:293 */
			clocks = < &rcc 0x44 0x10 >;   /* in zephyr/dts/arm/st/f4/stm32f4.dtsi:294 */
			resets = < &rctl 0x484 >;      /* in zephyr/dts/arm/st/f4/stm32f4.dtsi:295 */
			interrupts = < 0x25 0x0 >;     /* in zephyr/dts/arm/st/f4/stm32f4.dtsi:296 */
			status = "disabled";           /* in zephyr/dts/arm/st/f4/stm32f4.dtsi:297 */
		};

		/* node '/soc/serial@40004400' defined in zephyr/dts/arm/st/f4/stm32f4.dtsi:300 */
		usart2: serial@40004400 {
			compatible = "st,stm32-usart",
			             "st,stm32-uart";   /* in zephyr/dts/arm/st/f4/stm32f4.dtsi:301 */
			reg = < 0x40004400 0x400 >;     /* in zephyr/dts/arm/st/f4/stm32f4.dtsi:302 */
			clocks = < &rcc 0x40 0x20000 >; /* in zephyr/dts/arm/st/f4/stm32f4.dtsi:303 */
			resets = < &rctl 0x411 >;       /* in zephyr/dts/arm/st/f4/stm32f4.dtsi:304 */
			interrupts = < 0x26 0x0 >;      /* in zephyr/dts/arm/st/f4/stm32f4.dtsi:305 */
			status = "disabled";            /* in zephyr/dts/arm/st/f4/stm32f4.dtsi:306 */
		};

		/* node '/soc/serial@40011400' defined in zephyr/dts/arm/st/f4/stm32f4.dtsi:309 */
		usart6: arduino_serial: serial@40011400 {
			compatible = "st,stm32-usart",
			             "st,stm32-uart";                   /* in zephyr/dts/arm/st/f4/stm32f4.dtsi:310 */
			reg = < 0x40011400 0x400 >;                     /* in zephyr/dts/arm/st/f4/stm32f4.dtsi:311 */
			clocks = < &rcc 0x44 0x20 >;                    /* in zephyr/dts/arm/st/f4/stm32f4.dtsi:312 */
			resets = < &rctl 0x485 >;                       /* in zephyr/dts/arm/st/f4/stm32f4.dtsi:313 */
			interrupts = < 0x47 0x0 >;                      /* in zephyr/dts/arm/st/f4/stm32f4.dtsi:314 */
			pinctrl-0 = < &usart6_tx_pg14 &usart6_rx_pg9 >; /* in zephyr/boards/st/nucleo_f439zi/nucleo_f439zi.dts:145 */
			pinctrl-names = "default";                      /* in zephyr/boards/st/nucleo_f439zi/nucleo_f439zi.dts:146 */
			current-speed = < 0x1c200 >;                    /* in zephyr/boards/st/nucleo_f439zi/nucleo_f439zi.dts:147 */
			status = "okay";                                /* in zephyr/boards/st/nucleo_f439zi/nucleo_f439zi.dts:148 */
		};

		/* node '/soc/i2c@40005400' defined in zephyr/dts/arm/st/f4/stm32f4.dtsi:318 */
		i2c1: arduino_i2c: i2c@40005400 {
			compatible = "st,stm32-i2c-v1";              /* in zephyr/dts/arm/st/f4/stm32f4.dtsi:319 */
			#address-cells = < 0x1 >;                    /* in zephyr/dts/arm/st/f4/stm32f4.dtsi:321 */
			#size-cells = < 0x0 >;                       /* in zephyr/dts/arm/st/f4/stm32f4.dtsi:322 */
			reg = < 0x40005400 0x400 >;                  /* in zephyr/dts/arm/st/f4/stm32f4.dtsi:323 */
			clocks = < &rcc 0x40 0x200000 >;             /* in zephyr/dts/arm/st/f4/stm32f4.dtsi:324 */
			interrupts = < 0x1f 0x0 >,
			             < 0x20 0x0 >;                   /* in zephyr/dts/arm/st/f4/stm32f4.dtsi:325 */
			interrupt-names = "event",
			                  "error";                   /* in zephyr/dts/arm/st/f4/stm32f4.dtsi:326 */
			pinctrl-0 = < &i2c1_scl_pb8 &i2c1_sda_pb9 >; /* in zephyr/boards/st/nucleo_f439zi/nucleo_f439zi.dts:113 */
			pinctrl-names = "default";                   /* in zephyr/boards/st/nucleo_f439zi/nucleo_f439zi.dts:114 */
			scl-gpios = < &gpiob 0x8 0x0 >;              /* in zephyr/boards/st/nucleo_f439zi/nucleo_f439zi.dts:115 */
			sda-gpios = < &gpiob 0x9 0x0 >;              /* in zephyr/boards/st/nucleo_f439zi/nucleo_f439zi.dts:116 */
			status = "okay";                             /* in zephyr/boards/st/nucleo_f439zi/nucleo_f439zi.dts:117 */
			clock-frequency = < 0x61a80 >;               /* in zephyr/boards/st/nucleo_f439zi/nucleo_f439zi.dts:118 */
			phandle = < 0x2c >;                          /* in zephyr/dts/arm/st/f4/stm32f4.dtsi:711 */
		};

		/* node '/soc/i2c@40005800' defined in zephyr/dts/arm/st/f4/stm32f4.dtsi:330 */
		i2c2: i2c@40005800 {
			compatible = "st,stm32-i2c-v1";                /* in zephyr/dts/arm/st/f4/stm32f4.dtsi:331 */
			#address-cells = < 0x1 >;                      /* in zephyr/dts/arm/st/f4/stm32f4.dtsi:333 */
			#size-cells = < 0x0 >;                         /* in zephyr/dts/arm/st/f4/stm32f4.dtsi:334 */
			reg = < 0x40005800 0x400 >;                    /* in zephyr/dts/arm/st/f4/stm32f4.dtsi:335 */
			clocks = < &rcc 0x40 0x400000 >;               /* in zephyr/dts/arm/st/f4/stm32f4.dtsi:336 */
			interrupts = < 0x21 0x0 >,
			             < 0x22 0x0 >;                     /* in zephyr/dts/arm/st/f4/stm32f4.dtsi:337 */
			interrupt-names = "event",
			                  "error";                     /* in zephyr/dts/arm/st/f4/stm32f4.dtsi:338 */
			pinctrl-0 = < &i2c2_scl_pb10 &i2c2_sda_pb11 >; /* in zephyr/boards/st/nucleo_f439zi/nucleo_f439zi.dts:122 */
			pinctrl-names = "default";                     /* in zephyr/boards/st/nucleo_f439zi/nucleo_f439zi.dts:123 */
			scl-gpios = < &gpiob 0xa 0x0 >;                /* in zephyr/boards/st/nucleo_f439zi/nucleo_f439zi.dts:124 */
			sda-gpios = < &gpiob 0xb 0x0 >;                /* in zephyr/boards/st/nucleo_f439zi/nucleo_f439zi.dts:125 */
			status = "okay";                               /* in zephyr/boards/st/nucleo_f439zi/nucleo_f439zi.dts:126 */
			clock-frequency = < 0x61a80 >;                 /* in zephyr/boards/st/nucleo_f439zi/nucleo_f439zi.dts:127 */
			phandle = < 0x2d >;                            /* in zephyr/dts/arm/st/f4/stm32f4.dtsi:719 */
		};

		/* node '/soc/i2c@40005c00' defined in zephyr/dts/arm/st/f4/stm32f4.dtsi:342 */
		i2c3: i2c@40005c00 {
			compatible = "st,stm32-i2c-v1";  /* in zephyr/dts/arm/st/f4/stm32f4.dtsi:343 */
			clock-frequency = < 0x186a0 >;   /* in zephyr/dts/arm/st/f4/stm32f4.dtsi:344 */
			#address-cells = < 0x1 >;        /* in zephyr/dts/arm/st/f4/stm32f4.dtsi:345 */
			#size-cells = < 0x0 >;           /* in zephyr/dts/arm/st/f4/stm32f4.dtsi:346 */
			reg = < 0x40005c00 0x400 >;      /* in zephyr/dts/arm/st/f4/stm32f4.dtsi:347 */
			clocks = < &rcc 0x40 0x800000 >; /* in zephyr/dts/arm/st/f4/stm32f4.dtsi:348 */
			interrupts = < 0x48 0x0 >,
			             < 0x49 0x0 >;       /* in zephyr/dts/arm/st/f4/stm32f4.dtsi:349 */
			interrupt-names = "event",
			                  "error";       /* in zephyr/dts/arm/st/f4/stm32f4.dtsi:350 */
			status = "disabled";             /* in zephyr/dts/arm/st/f4/stm32f4.dtsi:351 */
			phandle = < 0x2e >;              /* in zephyr/dts/arm/st/f4/stm32f4.dtsi:727 */
		};

		/* node '/soc/spi@40013000' defined in zephyr/dts/arm/st/f4/stm32f4.dtsi:354 */
		spi1: arduino_spi: spi@40013000 {
			compatible = "st,stm32-spi";                                 /* in zephyr/dts/arm/st/f4/stm32f4.dtsi:355 */
			#address-cells = < 0x1 >;                                    /* in zephyr/dts/arm/st/f4/stm32f4.dtsi:356 */
			#size-cells = < 0x0 >;                                       /* in zephyr/dts/arm/st/f4/stm32f4.dtsi:357 */
			reg = < 0x40013000 0x400 >;                                  /* in zephyr/dts/arm/st/f4/stm32f4.dtsi:358 */
			clocks = < &rcc 0x44 0x1000 >;                               /* in zephyr/dts/arm/st/f4/stm32f4.dtsi:359 */
			interrupts = < 0x23 0x0 >;                                   /* in zephyr/dts/arm/st/f4/stm32f4.dtsi:360 */
			st,spi-data-width = "limited-8-16-bit";                      /* in zephyr/dts/arm/st/f4/stm32f4.dtsi:361 */
			pinctrl-0 = < &spi1_sck_pa5 &spi1_miso_pa6 &spi1_mosi_pa7 >; /* in zephyr/boards/st/nucleo_f439zi/nucleo_f439zi.dts:131 */
			pinctrl-names = "default";                                   /* in zephyr/boards/st/nucleo_f439zi/nucleo_f439zi.dts:132 */
			cs-gpios = < &gpiod 0xe 0x11 >;                              /* in zephyr/boards/st/nucleo_f439zi/nucleo_f439zi.dts:133 */
			status = "okay";                                             /* in zephyr/boards/st/nucleo_f439zi/nucleo_f439zi.dts:134 */
		};

		/* node '/soc/usb@50000000' defined in zephyr/dts/arm/st/f4/stm32f4.dtsi:365 */
		usbotg_fs: zephyr_udc0: usb@50000000 {
			compatible = "st,stm32-otgfs";                           /* in zephyr/dts/arm/st/f4/stm32f4.dtsi:366 */
			reg = < 0x50000000 0x40000 >;                            /* in zephyr/dts/arm/st/f4/stm32f4.dtsi:367 */
			interrupts = < 0x43 0x0 >;                               /* in zephyr/dts/arm/st/f4/stm32f4.dtsi:368 */
			interrupt-names = "otgfs";                               /* in zephyr/dts/arm/st/f4/stm32f4.dtsi:369 */
			num-bidir-endpoints = < 0x4 >;                           /* in zephyr/dts/arm/st/f4/stm32f4.dtsi:370 */
			ram-size = < 0x500 >;                                    /* in zephyr/dts/arm/st/f4/stm32f4.dtsi:371 */
			maximum-speed = "full-speed";                            /* in zephyr/dts/arm/st/f4/stm32f4.dtsi:372 */
			phys = < &otgfs_phy >;                                   /* in zephyr/dts/arm/st/f4/stm32f4.dtsi:373 */
			clocks = < &rcc 0x34 0x80 >,
			         < &rcc 0x7 0xff >;                              /* in zephyr/dts/arm/st/f4/stm32f4.dtsi:374 */
			pinctrl-0 = < &usb_otg_fs_dm_pa11 &usb_otg_fs_dp_pa12 >; /* in zephyr/boards/st/nucleo_f439zi/nucleo_f439zi.dts:152 */
			pinctrl-names = "default";                               /* in zephyr/boards/st/nucleo_f439zi/nucleo_f439zi.dts:153 */
			status = "okay";                                         /* in zephyr/boards/st/nucleo_f439zi/nucleo_f439zi.dts:154 */
		};

		/* node '/soc/timers@40010000' defined in zephyr/dts/arm/st/f4/stm32f4.dtsi:379 */
		timers1: timers@40010000 {
			compatible = "st,stm32-timers"; /* in zephyr/dts/arm/st/f4/stm32f4.dtsi:380 */
			reg = < 0x40010000 0x400 >;     /* in zephyr/dts/arm/st/f4/stm32f4.dtsi:381 */
			clocks = < &rcc 0x44 0x1 >,
			         < &rcc 0x16 0xff >;    /* in zephyr/dts/arm/st/f4/stm32f4.dtsi:382 */
			resets = < &rctl 0x480 >;       /* in zephyr/dts/arm/st/f4/stm32f4.dtsi:384 */
			interrupts = < 0x18 0x0 >,
			             < 0x19 0x0 >,
			             < 0x1a 0x0 >,
			             < 0x1b 0x0 >;      /* in zephyr/dts/arm/st/f4/stm32f4.dtsi:385 */
			interrupt-names = "brk",
			                  "up",
			                  "trgcom",
			                  "cc";         /* in zephyr/dts/arm/st/f4/stm32f4.dtsi:386 */
			st,prescaler = < 0x2710 >;      /* in zephyr/boards/st/nucleo_f439zi/nucleo_f439zi.dts:158 */
			status = "okay";                /* in zephyr/boards/st/nucleo_f439zi/nucleo_f439zi.dts:159 */

			/* node '/soc/timers@40010000/pwm' defined in zephyr/dts/arm/st/f4/stm32f4.dtsi:390 */
			pwm1: pwm {
				compatible = "st,stm32-pwm";    /* in zephyr/dts/arm/st/f4/stm32f4.dtsi:391 */
				#pwm-cells = < 0x3 >;           /* in zephyr/dts/arm/st/f4/stm32f4.dtsi:393 */
				status = "okay";                /* in zephyr/boards/st/nucleo_f439zi/nucleo_f439zi.dts:162 */
				pinctrl-0 = < &tim1_ch3_pe13 >; /* in zephyr/boards/st/nucleo_f439zi/nucleo_f439zi.dts:163 */
				pinctrl-names = "default";      /* in zephyr/boards/st/nucleo_f439zi/nucleo_f439zi.dts:164 */
			};

			/* node '/soc/timers@40010000/counter' defined in zephyr/dts/arm/st/f4/stm32f4.dtsi:396 */
			counter {
				compatible = "st,stm32-counter"; /* in zephyr/dts/arm/st/f4/stm32f4.dtsi:397 */
				status = "disabled";             /* in zephyr/dts/arm/st/f4/stm32f4.dtsi:398 */
			};

			/* node '/soc/timers@40010000/qdec' defined in zephyr/dts/arm/st/f4/stm32f4.dtsi:401 */
			qdec {
				compatible = "st,stm32-qdec";    /* in zephyr/dts/arm/st/f4/stm32f4.dtsi:402 */
				st,input-filter-level = < 0x0 >; /* in zephyr/dts/arm/st/f4/stm32f4.dtsi:403 */
				status = "disabled";             /* in zephyr/dts/arm/st/f4/stm32f4.dtsi:404 */
			};
		};

		/* node '/soc/timers@40000000' defined in zephyr/dts/arm/st/f4/stm32f4.dtsi:408 */
		timers2: timers@40000000 {
			compatible = "st,stm32-timers"; /* in zephyr/dts/arm/st/f4/stm32f4.dtsi:409 */
			reg = < 0x40000000 0x400 >;     /* in zephyr/dts/arm/st/f4/stm32f4.dtsi:410 */
			clocks = < &rcc 0x40 0x1 >,
			         < &rcc 0x15 0xff >;    /* in zephyr/dts/arm/st/f4/stm32f4.dtsi:411 */
			resets = < &rctl 0x400 >;       /* in zephyr/dts/arm/st/f4/stm32f4.dtsi:413 */
			interrupts = < 0x1c 0x0 >;      /* in zephyr/dts/arm/st/f4/stm32f4.dtsi:414 */
			interrupt-names = "global";     /* in zephyr/dts/arm/st/f4/stm32f4.dtsi:415 */
			st,prescaler = < 0x0 >;         /* in zephyr/dts/arm/st/f4/stm32f4.dtsi:416 */
			status = "disabled";            /* in zephyr/dts/arm/st/f4/stm32f4.dtsi:417 */

			/* node '/soc/timers@40000000/pwm' defined in zephyr/dts/arm/st/f4/stm32f4.dtsi:419 */
			pwm {
				compatible = "st,stm32-pwm"; /* in zephyr/dts/arm/st/f4/stm32f4.dtsi:420 */
				status = "disabled";         /* in zephyr/dts/arm/st/f4/stm32f4.dtsi:421 */
				#pwm-cells = < 0x3 >;        /* in zephyr/dts/arm/st/f4/stm32f4.dtsi:422 */
			};

			/* node '/soc/timers@40000000/counter' defined in zephyr/dts/arm/st/f4/stm32f4.dtsi:425 */
			counter {
				compatible = "st,stm32-counter"; /* in zephyr/dts/arm/st/f4/stm32f4.dtsi:426 */
				status = "disabled";             /* in zephyr/dts/arm/st/f4/stm32f4.dtsi:427 */
			};

			/* node '/soc/timers@40000000/qdec' defined in zephyr/dts/arm/st/f4/stm32f4.dtsi:430 */
			qdec {
				compatible = "st,stm32-qdec";    /* in zephyr/dts/arm/st/f4/stm32f4.dtsi:431 */
				st,input-filter-level = < 0x0 >; /* in zephyr/dts/arm/st/f4/stm32f4.dtsi:432 */
				status = "disabled";             /* in zephyr/dts/arm/st/f4/stm32f4.dtsi:433 */
			};
		};

		/* node '/soc/timers@40000400' defined in zephyr/dts/arm/st/f4/stm32f4.dtsi:437 */
		timers3: timers@40000400 {
			compatible = "st,stm32-timers"; /* in zephyr/dts/arm/st/f4/stm32f4.dtsi:438 */
			reg = < 0x40000400 0x400 >;     /* in zephyr/dts/arm/st/f4/stm32f4.dtsi:439 */
			clocks = < &rcc 0x40 0x2 >,
			         < &rcc 0x15 0xff >;    /* in zephyr/dts/arm/st/f4/stm32f4.dtsi:440 */
			resets = < &rctl 0x401 >;       /* in zephyr/dts/arm/st/f4/stm32f4.dtsi:442 */
			interrupts = < 0x1d 0x0 >;      /* in zephyr/dts/arm/st/f4/stm32f4.dtsi:443 */
			interrupt-names = "global";     /* in zephyr/dts/arm/st/f4/stm32f4.dtsi:444 */
			st,prescaler = < 0x0 >;         /* in zephyr/dts/arm/st/f4/stm32f4.dtsi:445 */
			status = "disabled";            /* in zephyr/dts/arm/st/f4/stm32f4.dtsi:446 */

			/* node '/soc/timers@40000400/pwm' defined in zephyr/dts/arm/st/f4/stm32f4.dtsi:448 */
			pwm {
				compatible = "st,stm32-pwm"; /* in zephyr/dts/arm/st/f4/stm32f4.dtsi:449 */
				status = "disabled";         /* in zephyr/dts/arm/st/f4/stm32f4.dtsi:450 */
				#pwm-cells = < 0x3 >;        /* in zephyr/dts/arm/st/f4/stm32f4.dtsi:451 */
			};

			/* node '/soc/timers@40000400/counter' defined in zephyr/dts/arm/st/f4/stm32f4.dtsi:454 */
			counter {
				compatible = "st,stm32-counter"; /* in zephyr/dts/arm/st/f4/stm32f4.dtsi:455 */
				status = "disabled";             /* in zephyr/dts/arm/st/f4/stm32f4.dtsi:456 */
			};

			/* node '/soc/timers@40000400/qdec' defined in zephyr/dts/arm/st/f4/stm32f4.dtsi:459 */
			qdec {
				compatible = "st,stm32-qdec";    /* in zephyr/dts/arm/st/f4/stm32f4.dtsi:460 */
				st,input-filter-level = < 0x0 >; /* in zephyr/dts/arm/st/f4/stm32f4.dtsi:461 */
				status = "disabled";             /* in zephyr/dts/arm/st/f4/stm32f4.dtsi:462 */
			};
		};

		/* node '/soc/timers@40000800' defined in zephyr/dts/arm/st/f4/stm32f4.dtsi:466 */
		timers4: timers@40000800 {
			compatible = "st,stm32-timers"; /* in zephyr/dts/arm/st/f4/stm32f4.dtsi:467 */
			reg = < 0x40000800 0x400 >;     /* in zephyr/dts/arm/st/f4/stm32f4.dtsi:468 */
			clocks = < &rcc 0x40 0x4 >,
			         < &rcc 0x15 0xff >;    /* in zephyr/dts/arm/st/f4/stm32f4.dtsi:469 */
			resets = < &rctl 0x402 >;       /* in zephyr/dts/arm/st/f4/stm32f4.dtsi:471 */
			interrupts = < 0x1e 0x0 >;      /* in zephyr/dts/arm/st/f4/stm32f4.dtsi:472 */
			interrupt-names = "global";     /* in zephyr/dts/arm/st/f4/stm32f4.dtsi:473 */
			st,prescaler = < 0x0 >;         /* in zephyr/dts/arm/st/f4/stm32f4.dtsi:474 */
			status = "disabled";            /* in zephyr/dts/arm/st/f4/stm32f4.dtsi:475 */

			/* node '/soc/timers@40000800/pwm' defined in zephyr/dts/arm/st/f4/stm32f4.dtsi:477 */
			pwm {
				compatible = "st,stm32-pwm"; /* in zephyr/dts/arm/st/f4/stm32f4.dtsi:478 */
				status = "disabled";         /* in zephyr/dts/arm/st/f4/stm32f4.dtsi:479 */
				#pwm-cells = < 0x3 >;        /* in zephyr/dts/arm/st/f4/stm32f4.dtsi:480 */
			};

			/* node '/soc/timers@40000800/counter' defined in zephyr/dts/arm/st/f4/stm32f4.dtsi:483 */
			counter {
				compatible = "st,stm32-counter"; /* in zephyr/dts/arm/st/f4/stm32f4.dtsi:484 */
				status = "disabled";             /* in zephyr/dts/arm/st/f4/stm32f4.dtsi:485 */
			};

			/* node '/soc/timers@40000800/qdec' defined in zephyr/dts/arm/st/f4/stm32f4.dtsi:488 */
			qdec {
				compatible = "st,stm32-qdec";    /* in zephyr/dts/arm/st/f4/stm32f4.dtsi:489 */
				st,input-filter-level = < 0x0 >; /* in zephyr/dts/arm/st/f4/stm32f4.dtsi:490 */
				status = "disabled";             /* in zephyr/dts/arm/st/f4/stm32f4.dtsi:491 */
			};
		};

		/* node '/soc/timers@40000c00' defined in zephyr/dts/arm/st/f4/stm32f4.dtsi:495 */
		timers5: timers@40000c00 {
			compatible = "st,stm32-timers"; /* in zephyr/dts/arm/st/f4/stm32f4.dtsi:496 */
			reg = < 0x40000c00 0x400 >;     /* in zephyr/dts/arm/st/f4/stm32f4.dtsi:497 */
			clocks = < &rcc 0x40 0x8 >,
			         < &rcc 0x15 0xff >;    /* in zephyr/dts/arm/st/f4/stm32f4.dtsi:498 */
			resets = < &rctl 0x403 >;       /* in zephyr/dts/arm/st/f4/stm32f4.dtsi:500 */
			interrupts = < 0x32 0x0 >;      /* in zephyr/dts/arm/st/f4/stm32f4.dtsi:501 */
			interrupt-names = "global";     /* in zephyr/dts/arm/st/f4/stm32f4.dtsi:502 */
			st,prescaler = < 0x0 >;         /* in zephyr/dts/arm/st/f4/stm32f4.dtsi:503 */
			status = "disabled";            /* in zephyr/dts/arm/st/f4/stm32f4.dtsi:504 */

			/* node '/soc/timers@40000c00/pwm' defined in zephyr/dts/arm/st/f4/stm32f4.dtsi:506 */
			pwm {
				compatible = "st,stm32-pwm"; /* in zephyr/dts/arm/st/f4/stm32f4.dtsi:507 */
				status = "disabled";         /* in zephyr/dts/arm/st/f4/stm32f4.dtsi:508 */
				#pwm-cells = < 0x3 >;        /* in zephyr/dts/arm/st/f4/stm32f4.dtsi:509 */
			};

			/* node '/soc/timers@40000c00/counter' defined in zephyr/dts/arm/st/f4/stm32f4.dtsi:512 */
			counter {
				compatible = "st,stm32-counter"; /* in zephyr/dts/arm/st/f4/stm32f4.dtsi:513 */
				status = "disabled";             /* in zephyr/dts/arm/st/f4/stm32f4.dtsi:514 */
			};

			/* node '/soc/timers@40000c00/qdec' defined in zephyr/dts/arm/st/f4/stm32f4.dtsi:517 */
			qdec {
				compatible = "st,stm32-qdec";    /* in zephyr/dts/arm/st/f4/stm32f4.dtsi:518 */
				st,input-filter-level = < 0x0 >; /* in zephyr/dts/arm/st/f4/stm32f4.dtsi:519 */
				status = "disabled";             /* in zephyr/dts/arm/st/f4/stm32f4.dtsi:520 */
			};
		};

		/* node '/soc/timers@40014000' defined in zephyr/dts/arm/st/f4/stm32f4.dtsi:524 */
		timers9: timers@40014000 {
			compatible = "st,stm32-timers"; /* in zephyr/dts/arm/st/f4/stm32f4.dtsi:525 */
			reg = < 0x40014000 0x400 >;     /* in zephyr/dts/arm/st/f4/stm32f4.dtsi:526 */
			clocks = < &rcc 0x44 0x10000 >,
			         < &rcc 0x16 0xff >;    /* in zephyr/dts/arm/st/f4/stm32f4.dtsi:527 */
			resets = < &rctl 0x490 >;       /* in zephyr/dts/arm/st/f4/stm32f4.dtsi:529 */
			interrupts = < 0x18 0x0 >;      /* in zephyr/dts/arm/st/f4/stm32f4.dtsi:530 */
			interrupt-names = "global";     /* in zephyr/dts/arm/st/f4/stm32f4.dtsi:531 */
			st,prescaler = < 0x0 >;         /* in zephyr/dts/arm/st/f4/stm32f4.dtsi:532 */
			status = "disabled";            /* in zephyr/dts/arm/st/f4/stm32f4.dtsi:533 */

			/* node '/soc/timers@40014000/pwm' defined in zephyr/dts/arm/st/f4/stm32f4.dtsi:535 */
			pwm {
				compatible = "st,stm32-pwm"; /* in zephyr/dts/arm/st/f4/stm32f4.dtsi:536 */
				status = "disabled";         /* in zephyr/dts/arm/st/f4/stm32f4.dtsi:537 */
				#pwm-cells = < 0x3 >;        /* in zephyr/dts/arm/st/f4/stm32f4.dtsi:538 */
			};

			/* node '/soc/timers@40014000/counter' defined in zephyr/dts/arm/st/f4/stm32f4.dtsi:541 */
			counter {
				compatible = "st,stm32-counter"; /* in zephyr/dts/arm/st/f4/stm32f4.dtsi:542 */
				status = "disabled";             /* in zephyr/dts/arm/st/f4/stm32f4.dtsi:543 */
			};
		};

		/* node '/soc/timers@40014400' defined in zephyr/dts/arm/st/f4/stm32f4.dtsi:547 */
		timers10: timers@40014400 {
			compatible = "st,stm32-timers"; /* in zephyr/dts/arm/st/f4/stm32f4.dtsi:548 */
			reg = < 0x40014400 0x400 >;     /* in zephyr/dts/arm/st/f4/stm32f4.dtsi:549 */
			clocks = < &rcc 0x44 0x20000 >,
			         < &rcc 0x16 0xff >;    /* in zephyr/dts/arm/st/f4/stm32f4.dtsi:550 */
			resets = < &rctl 0x491 >;       /* in zephyr/dts/arm/st/f4/stm32f4.dtsi:552 */
			interrupts = < 0x19 0x0 >;      /* in zephyr/dts/arm/st/f4/stm32f4.dtsi:553 */
			interrupt-names = "global";     /* in zephyr/dts/arm/st/f4/stm32f4.dtsi:554 */
			st,prescaler = < 0x0 >;         /* in zephyr/dts/arm/st/f4/stm32f4.dtsi:555 */
			status = "disabled";            /* in zephyr/dts/arm/st/f4/stm32f4.dtsi:556 */

			/* node '/soc/timers@40014400/pwm' defined in zephyr/dts/arm/st/f4/stm32f4.dtsi:558 */
			pwm {
				compatible = "st,stm32-pwm"; /* in zephyr/dts/arm/st/f4/stm32f4.dtsi:559 */
				status = "disabled";         /* in zephyr/dts/arm/st/f4/stm32f4.dtsi:560 */
				#pwm-cells = < 0x3 >;        /* in zephyr/dts/arm/st/f4/stm32f4.dtsi:561 */
			};

			/* node '/soc/timers@40014400/counter' defined in zephyr/dts/arm/st/f4/stm32f4.dtsi:564 */
			counter {
				compatible = "st,stm32-counter"; /* in zephyr/dts/arm/st/f4/stm32f4.dtsi:565 */
				status = "disabled";             /* in zephyr/dts/arm/st/f4/stm32f4.dtsi:566 */
			};
		};

		/* node '/soc/timers@40014800' defined in zephyr/dts/arm/st/f4/stm32f4.dtsi:570 */
		timers11: timers@40014800 {
			compatible = "st,stm32-timers"; /* in zephyr/dts/arm/st/f4/stm32f4.dtsi:571 */
			reg = < 0x40014800 0x400 >;     /* in zephyr/dts/arm/st/f4/stm32f4.dtsi:572 */
			clocks = < &rcc 0x44 0x40000 >,
			         < &rcc 0x16 0xff >;    /* in zephyr/dts/arm/st/f4/stm32f4.dtsi:573 */
			resets = < &rctl 0x492 >;       /* in zephyr/dts/arm/st/f4/stm32f4.dtsi:575 */
			interrupts = < 0x1a 0x0 >;      /* in zephyr/dts/arm/st/f4/stm32f4.dtsi:576 */
			interrupt-names = "global";     /* in zephyr/dts/arm/st/f4/stm32f4.dtsi:577 */
			st,prescaler = < 0x0 >;         /* in zephyr/dts/arm/st/f4/stm32f4.dtsi:578 */
			status = "disabled";            /* in zephyr/dts/arm/st/f4/stm32f4.dtsi:579 */

			/* node '/soc/timers@40014800/pwm' defined in zephyr/dts/arm/st/f4/stm32f4.dtsi:581 */
			pwm {
				compatible = "st,stm32-pwm"; /* in zephyr/dts/arm/st/f4/stm32f4.dtsi:582 */
				status = "disabled";         /* in zephyr/dts/arm/st/f4/stm32f4.dtsi:583 */
				#pwm-cells = < 0x3 >;        /* in zephyr/dts/arm/st/f4/stm32f4.dtsi:584 */
			};

			/* node '/soc/timers@40014800/counter' defined in zephyr/dts/arm/st/f4/stm32f4.dtsi:587 */
			counter {
				compatible = "st,stm32-counter"; /* in zephyr/dts/arm/st/f4/stm32f4.dtsi:588 */
				status = "disabled";             /* in zephyr/dts/arm/st/f4/stm32f4.dtsi:589 */
			};
		};

		/* node '/soc/rtc@40002800' defined in zephyr/dts/arm/st/f4/stm32f4.dtsi:593 */
		rtc: rtc@40002800 {
			compatible = "st,stm32-rtc";       /* in zephyr/dts/arm/st/f4/stm32f4.dtsi:594 */
			reg = < 0x40002800 0x400 >;        /* in zephyr/dts/arm/st/f4/stm32f4.dtsi:595 */
			interrupts = < 0x29 0x0 >;         /* in zephyr/dts/arm/st/f4/stm32f4.dtsi:596 */
			prescaler = < 0x8000 >;            /* in zephyr/dts/arm/st/f4/stm32f4.dtsi:598 */
			alarms-count = < 0x2 >;            /* in zephyr/dts/arm/st/f4/stm32f4.dtsi:599 */
			alrm-exti-line = < 0x11 >;         /* in zephyr/dts/arm/st/f4/stm32f4.dtsi:600 */
			clocks = < &rcc 0x40 0x10000000 >,
			         < &rcc 0x3 0x2280070 >;   /* in zephyr/boards/st/nucleo_f439zi/nucleo_f439zi.dts:169 */
			status = "okay";                   /* in zephyr/boards/st/nucleo_f439zi/nucleo_f439zi.dts:171 */

			/* node '/soc/rtc@40002800/backup_regs' defined in zephyr/dts/arm/st/f4/stm32f4.dtsi:603 */
			bbram: backup_regs {
				compatible = "st,stm32-bbram"; /* in zephyr/dts/arm/st/f4/stm32f4.dtsi:604 */
				st,backup-regs = < 0x14 >;     /* in zephyr/dts/arm/st/f4/stm32f4.dtsi:605 */
				status = "disabled";           /* in zephyr/dts/arm/st/f4/stm32f4.dtsi:606 */
			};
		};

		/* node '/soc/adc@40012000' defined in zephyr/dts/arm/st/f4/stm32f4.dtsi:610 */
		adc1: adc@40012000 {
			compatible = "st,stm32f4-adc",
			             "st,stm32-adc";                                 /* in zephyr/dts/arm/st/f4/stm32f4.dtsi:611 */
			reg = < 0x40012000 0x400 >;                                  /* in zephyr/dts/arm/st/f4/stm32f4.dtsi:612 */
			clocks = < &rcc 0x44 0x100 >;                                /* in zephyr/dts/arm/st/f4/stm32f4.dtsi:613 */
			clock-names = "adcx";                                        /* in zephyr/dts/arm/st/f4/stm32f4.dtsi:614 */
			interrupts = < 0x12 0x0 >;                                   /* in zephyr/dts/arm/st/f4/stm32f4.dtsi:615 */
			#io-channel-cells = < 0x1 >;                                 /* in zephyr/dts/arm/st/f4/stm32f4.dtsi:616 */
			st,adc-resolutions = < 0xc 0xa 0x8 0x6 >;                    /* in zephyr/dts/arm/st/f4/stm32f4.dtsi:617 */
			sampling-times = < 0x3 0xf 0x1c 0x38 0x54 0x70 0x90 0x1e0 >; /* in zephyr/dts/arm/st/f4/stm32f4.dtsi:618 */
			st,adc-sequencer = "programmable";                           /* in zephyr/dts/arm/st/f4/stm32f4.dtsi:620 */
			st,adc-oversampler = "none";                                 /* in zephyr/dts/arm/st/f4/stm32f4.dtsi:621 */
			st,adc-internal-regulator = "none";                          /* in zephyr/dts/arm/st/f4/stm32f4.dtsi:622 */
			st,adc-has-injected-support;                                 /* in zephyr/dts/arm/st/f4/stm32f4.dtsi:623 */
			pinctrl-0 = < &adc1_in0_pa0 >;                               /* in zephyr/boards/st/nucleo_f439zi/nucleo_f439zi.dts:95 */
			pinctrl-names = "default";                                   /* in zephyr/boards/st/nucleo_f439zi/nucleo_f439zi.dts:96 */
			st,adc-clock-source = "SYNC";                                /* in zephyr/boards/st/nucleo_f439zi/nucleo_f439zi.dts:97 */
			st,adc-prescaler = < 0x2 >;                                  /* in zephyr/boards/st/nucleo_f439zi/nucleo_f439zi.dts:98 */
			status = "okay";                                             /* in zephyr/boards/st/nucleo_f439zi/nucleo_f439zi.dts:99 */
			phandle = < 0x2a >;                                          /* in zephyr/dts/arm/st/f4/stm32f427.dtsi:148 */
		};

		/* node '/soc/dma@40026000' defined in zephyr/dts/arm/st/f4/stm32f4.dtsi:627 */
		dma1: dma@40026000 {
			compatible = "st,stm32-dma-v1";  /* in zephyr/dts/arm/st/f4/stm32f4.dtsi:628 */
			#dma-cells = < 0x4 >;            /* in zephyr/dts/arm/st/f4/stm32f4.dtsi:629 */
			reg = < 0x40026000 0x400 >;      /* in zephyr/dts/arm/st/f4/stm32f4.dtsi:630 */
			interrupts = < 0xb 0x0 >,
			             < 0xc 0x0 >,
			             < 0xd 0x0 >,
			             < 0xe 0x0 >,
			             < 0xf 0x0 >,
			             < 0x10 0x0 >,
			             < 0x11 0x0 >,
			             < 0x2f 0x0 >;       /* in zephyr/dts/arm/st/f4/stm32f4.dtsi:631 */
			clocks = < &rcc 0x30 0x200000 >; /* in zephyr/dts/arm/st/f4/stm32f4.dtsi:632 */
			status = "disabled";             /* in zephyr/dts/arm/st/f4/stm32f4.dtsi:633 */
			phandle = < 0x16 >;              /* in zephyr/dts/arm/st/f4/stm32f401.dtsi:61 */
		};

		/* node '/soc/dma@40026400' defined in zephyr/dts/arm/st/f4/stm32f4.dtsi:636 */
		dma2: dma@40026400 {
			compatible = "st,stm32-dma-v1";  /* in zephyr/dts/arm/st/f4/stm32f4.dtsi:637 */
			#dma-cells = < 0x4 >;            /* in zephyr/dts/arm/st/f4/stm32f4.dtsi:638 */
			reg = < 0x40026400 0x400 >;      /* in zephyr/dts/arm/st/f4/stm32f4.dtsi:639 */
			interrupts = < 0x38 0x0 >,
			             < 0x39 0x0 >,
			             < 0x3a 0x0 >,
			             < 0x3b 0x0 >,
			             < 0x3c 0x0 >,
			             < 0x44 0x0 >,
			             < 0x45 0x0 >,
			             < 0x46 0x0 >;       /* in zephyr/dts/arm/st/f4/stm32f4.dtsi:640 */
			clocks = < &rcc 0x30 0x400000 >; /* in zephyr/dts/arm/st/f4/stm32f4.dtsi:641 */
			st,mem2mem;                      /* in zephyr/dts/arm/st/f4/stm32f4.dtsi:642 */
			status = "okay";                 /* in zephyr/boards/st/nucleo_f439zi/nucleo_f439zi.dts:183 */
			phandle = < 0x25 >;              /* in zephyr/dts/arm/st/f4/stm32f427.dtsi:131 */
		};

		/* node '/soc/sdmmc@40012c00' defined in zephyr/dts/arm/st/f4/stm32f4.dtsi:646 */
		sdmmc1: sdmmc@40012c00 {
			compatible = "st,stm32-sdmmc"; /* in zephyr/dts/arm/st/f4/stm32f4.dtsi:647 */
			reg = < 0x40012c00 0x400 >;    /* in zephyr/dts/arm/st/f4/stm32f4.dtsi:648 */
			clocks = < &rcc 0x44 0x800 >,
			         < &rcc 0x7 0xff >;    /* in zephyr/dts/arm/st/f4/stm32f4.dtsi:649 */
			resets = < &rctl 0x48b >;      /* in zephyr/dts/arm/st/f4/stm32f4.dtsi:651 */
			interrupts = < 0x31 0x0 >;     /* in zephyr/dts/arm/st/f4/stm32f4.dtsi:652 */
			status = "disabled";           /* in zephyr/dts/arm/st/f4/stm32f4.dtsi:653 */
		};

		/* node '/soc/power@40007000' defined in zephyr/dts/arm/st/f4/stm32f4.dtsi:656 */
		pwr: power@40007000 {
			compatible = "st,stm32-pwr"; /* in zephyr/dts/arm/st/f4/stm32f4.dtsi:657 */
			reg = < 0x40007000 0x400 >;  /* in zephyr/dts/arm/st/f4/stm32f4.dtsi:658 */

			/* node '/soc/power@40007000/wakeup-controller' defined in zephyr/dts/arm/st/f4/stm32f4.dtsi:660 */
			wakeup-controller {
				compatible = "st,stm32f1-pwr-wkupctrl",
				             "st,stm32-pwr-wkupctrl";   /* in zephyr/dts/arm/st/f4/stm32f4.dtsi:661 */
				#address-cells = < 0x1 >;               /* in zephyr/dts/arm/st/f4/stm32f4.dtsi:662 */
				#size-cells = < 0x0 >;                  /* in zephyr/dts/arm/st/f4/stm32f4.dtsi:663 */
				status = "disabled";                    /* in zephyr/dts/arm/st/f4/stm32f4.dtsi:664 */
				st,max-wkup-line-idx = < 0x1 >;         /* in zephyr/dts/arm/st/f4/stm32f4.dtsi:666 */

				/* node '/soc/power@40007000/wakeup-controller/wkup@1' defined in zephyr/dts/arm/st/f4/stm32f4.dtsi:668 */
				wkup@1 {
					reg = < 0x1 >;                   /* in zephyr/dts/arm/st/f4/stm32f4.dtsi:669 */
					wkup-gpios = < &gpioa 0x0 0x0 >; /* in zephyr/dts/arm/st/f4/stm32f4.dtsi:670 */
				};
			};
		};

		/* node '/soc/spi@40003800' defined in zephyr/dts/arm/st/f4/stm32f401.dtsi:21 */
		spi2: spi@40003800 {
			compatible = "st,stm32-spi";            /* in zephyr/dts/arm/st/f4/stm32f401.dtsi:22 */
			#address-cells = < 0x1 >;               /* in zephyr/dts/arm/st/f4/stm32f401.dtsi:23 */
			#size-cells = < 0x0 >;                  /* in zephyr/dts/arm/st/f4/stm32f401.dtsi:24 */
			reg = < 0x40003800 0x400 >;             /* in zephyr/dts/arm/st/f4/stm32f401.dtsi:25 */
			clocks = < &rcc 0x40 0x4000 >;          /* in zephyr/dts/arm/st/f4/stm32f401.dtsi:26 */
			interrupts = < 0x24 0x0 >;              /* in zephyr/dts/arm/st/f4/stm32f401.dtsi:27 */
			st,spi-data-width = "limited-8-16-bit"; /* in zephyr/dts/arm/st/f4/stm32f401.dtsi:28 */
			status = "disabled";                    /* in zephyr/dts/arm/st/f4/stm32f401.dtsi:29 */
		};

		/* node '/soc/spi@40003c00' defined in zephyr/dts/arm/st/f4/stm32f401.dtsi:32 */
		spi3: spi@40003c00 {
			compatible = "st,stm32-spi";            /* in zephyr/dts/arm/st/f4/stm32f401.dtsi:33 */
			#address-cells = < 0x1 >;               /* in zephyr/dts/arm/st/f4/stm32f401.dtsi:34 */
			#size-cells = < 0x0 >;                  /* in zephyr/dts/arm/st/f4/stm32f401.dtsi:35 */
			reg = < 0x40003c00 0x400 >;             /* in zephyr/dts/arm/st/f4/stm32f401.dtsi:36 */
			clocks = < &rcc 0x40 0x8000 >;          /* in zephyr/dts/arm/st/f4/stm32f401.dtsi:37 */
			interrupts = < 0x33 0x0 >;              /* in zephyr/dts/arm/st/f4/stm32f401.dtsi:38 */
			st,spi-data-width = "limited-8-16-bit"; /* in zephyr/dts/arm/st/f4/stm32f401.dtsi:39 */
			status = "disabled";                    /* in zephyr/dts/arm/st/f4/stm32f401.dtsi:40 */
		};

		/* node '/soc/spi@40013400' defined in zephyr/dts/arm/st/f4/stm32f401.dtsi:43 */
		spi4: spi@40013400 {
			compatible = "st,stm32-spi";            /* in zephyr/dts/arm/st/f4/stm32f427.dtsi:67 */
			#address-cells = < 0x1 >;               /* in zephyr/dts/arm/st/f4/stm32f427.dtsi:68 */
			#size-cells = < 0x0 >;                  /* in zephyr/dts/arm/st/f4/stm32f427.dtsi:69 */
			reg = < 0x40013400 0x400 >;             /* in zephyr/dts/arm/st/f4/stm32f427.dtsi:70 */
			clocks = < &rcc 0x44 0x2000 >;          /* in zephyr/dts/arm/st/f4/stm32f427.dtsi:71 */
			interrupts = < 0x54 0x0 >;              /* in zephyr/dts/arm/st/f4/stm32f427.dtsi:72 */
			st,spi-data-width = "limited-8-16-bit"; /* in zephyr/dts/arm/st/f4/stm32f427.dtsi:73 */
			status = "disabled";                    /* in zephyr/dts/arm/st/f4/stm32f427.dtsi:74 */
		};

		/* node '/soc/i2s@40003800' defined in zephyr/dts/arm/st/f4/stm32f401.dtsi:54 */
		i2s2: i2s@40003800 {
			compatible = "st,stm32-i2s";        /* in zephyr/dts/arm/st/f4/stm32f401.dtsi:55 */
			#address-cells = < 0x1 >;           /* in zephyr/dts/arm/st/f4/stm32f401.dtsi:56 */
			#size-cells = < 0x0 >;              /* in zephyr/dts/arm/st/f4/stm32f401.dtsi:57 */
			reg = < 0x40003800 0x400 >;         /* in zephyr/dts/arm/st/f4/stm32f401.dtsi:58 */
			clocks = < &rcc 0x40 0x4000 >;      /* in zephyr/dts/arm/st/f4/stm32f401.dtsi:59 */
			interrupts = < 0x24 0x0 >;          /* in zephyr/dts/arm/st/f4/stm32f401.dtsi:60 */
			dmas = < &dma1 0x4 0x0 0x400 0x3 >,
			       < &dma1 0x3 0x0 0x400 0x3 >; /* in zephyr/dts/arm/st/f4/stm32f401.dtsi:61 */
			dma-names = "tx",
			            "rx";                   /* in zephyr/dts/arm/st/f4/stm32f401.dtsi:63 */
			status = "disabled";                /* in zephyr/dts/arm/st/f4/stm32f401.dtsi:64 */
		};

		/* node '/soc/i2s@40003c00' defined in zephyr/dts/arm/st/f4/stm32f401.dtsi:67 */
		i2s3: i2s@40003c00 {
			compatible = "st,stm32-i2s";        /* in zephyr/dts/arm/st/f4/stm32f401.dtsi:68 */
			#address-cells = < 0x1 >;           /* in zephyr/dts/arm/st/f4/stm32f401.dtsi:69 */
			#size-cells = < 0x0 >;              /* in zephyr/dts/arm/st/f4/stm32f401.dtsi:70 */
			reg = < 0x40003c00 0x400 >;         /* in zephyr/dts/arm/st/f4/stm32f401.dtsi:71 */
			clocks = < &rcc 0x40 0x8000 >;      /* in zephyr/dts/arm/st/f4/stm32f401.dtsi:72 */
			interrupts = < 0x33 0x0 >;          /* in zephyr/dts/arm/st/f4/stm32f401.dtsi:73 */
			dmas = < &dma1 0x5 0x0 0x400 0x3 >,
			       < &dma1 0x0 0x0 0x400 0x3 >; /* in zephyr/dts/arm/st/f4/stm32f401.dtsi:74 */
			dma-names = "tx",
			            "rx";                   /* in zephyr/dts/arm/st/f4/stm32f401.dtsi:76 */
			status = "disabled";                /* in zephyr/dts/arm/st/f4/stm32f401.dtsi:77 */
		};

		/* node '/soc/serial@40004800' defined in zephyr/dts/arm/st/f4/stm32f405.dtsi:51 */
		usart3: serial@40004800 {
			compatible = "st,stm32-usart",
			             "st,stm32-uart";                  /* in zephyr/dts/arm/st/f4/stm32f405.dtsi:52 */
			reg = < 0x40004800 0x400 >;                    /* in zephyr/dts/arm/st/f4/stm32f405.dtsi:53 */
			clocks = < &rcc 0x40 0x40000 >;                /* in zephyr/dts/arm/st/f4/stm32f405.dtsi:54 */
			resets = < &rctl 0x412 >;                      /* in zephyr/dts/arm/st/f4/stm32f405.dtsi:55 */
			interrupts = < 0x27 0x0 >;                     /* in zephyr/dts/arm/st/f4/stm32f405.dtsi:56 */
			pinctrl-0 = < &usart3_tx_pd8 &usart3_rx_pd9 >; /* in zephyr/boards/st/nucleo_f439zi/nucleo_f439zi.dts:138 */
			pinctrl-names = "default";                     /* in zephyr/boards/st/nucleo_f439zi/nucleo_f439zi.dts:139 */
			status = "okay";                               /* in ../../../../development/germany/sm3/research/can_t1s_latency_bench/host-tools/demo/terminal_config/build/zephyr/boards/nucleo_f439zi.overlay:9 */
			current-speed = < 0x1c200 >;                   /* in ../../../../development/germany/sm3/research/can_t1s_latency_bench/host-tools/demo/terminal_config/build/zephyr/boards/nucleo_f439zi.overlay:10 */
		};

		/* node '/soc/serial@40004c00' defined in zephyr/dts/arm/st/f4/stm32f405.dtsi:60 */
		uart4: serial@40004c00 {
			compatible = "st,stm32-uart";   /* in zephyr/dts/arm/st/f4/stm32f405.dtsi:61 */
			reg = < 0x40004c00 0x400 >;     /* in zephyr/dts/arm/st/f4/stm32f405.dtsi:62 */
			clocks = < &rcc 0x40 0x80000 >; /* in zephyr/dts/arm/st/f4/stm32f405.dtsi:63 */
			resets = < &rctl 0x413 >;       /* in zephyr/dts/arm/st/f4/stm32f405.dtsi:64 */
			interrupts = < 0x34 0x0 >;      /* in zephyr/dts/arm/st/f4/stm32f405.dtsi:65 */
			status = "disabled";            /* in zephyr/dts/arm/st/f4/stm32f405.dtsi:66 */
		};

		/* node '/soc/serial@40005000' defined in zephyr/dts/arm/st/f4/stm32f405.dtsi:69 */
		uart5: serial@40005000 {
			compatible = "st,stm32-uart";    /* in zephyr/dts/arm/st/f4/stm32f405.dtsi:70 */
			reg = < 0x40005000 0x400 >;      /* in zephyr/dts/arm/st/f4/stm32f405.dtsi:71 */
			clocks = < &rcc 0x40 0x100000 >; /* in zephyr/dts/arm/st/f4/stm32f405.dtsi:72 */
			resets = < &rctl 0x414 >;        /* in zephyr/dts/arm/st/f4/stm32f405.dtsi:73 */
			interrupts = < 0x35 0x0 >;       /* in zephyr/dts/arm/st/f4/stm32f405.dtsi:74 */
			status = "disabled";             /* in zephyr/dts/arm/st/f4/stm32f405.dtsi:75 */
		};

		/* node '/soc/timers@40001000' defined in zephyr/dts/arm/st/f4/stm32f405.dtsi:78 */
		timers6: timers@40001000 {
			compatible = "st,stm32-timers"; /* in zephyr/dts/arm/st/f4/stm32f405.dtsi:79 */
			reg = < 0x40001000 0x400 >;     /* in zephyr/dts/arm/st/f4/stm32f405.dtsi:80 */
			clocks = < &rcc 0x40 0x10 >,
			         < &rcc 0x15 0xff >;    /* in zephyr/dts/arm/st/f4/stm32f405.dtsi:81 */
			resets = < &rctl 0x404 >;       /* in zephyr/dts/arm/st/f4/stm32f405.dtsi:83 */
			interrupts = < 0x36 0x0 >;      /* in zephyr/dts/arm/st/f4/stm32f405.dtsi:84 */
			interrupt-names = "global";     /* in zephyr/dts/arm/st/f4/stm32f405.dtsi:85 */
			st,prescaler = < 0x0 >;         /* in zephyr/dts/arm/st/f4/stm32f405.dtsi:86 */
			status = "disabled";            /* in zephyr/dts/arm/st/f4/stm32f405.dtsi:87 */

			/* node '/soc/timers@40001000/counter' defined in zephyr/dts/arm/st/f4/stm32f405.dtsi:89 */
			counter {
				compatible = "st,stm32-counter"; /* in zephyr/dts/arm/st/f4/stm32f405.dtsi:90 */
				status = "disabled";             /* in zephyr/dts/arm/st/f4/stm32f405.dtsi:91 */
			};
		};

		/* node '/soc/timers@40001400' defined in zephyr/dts/arm/st/f4/stm32f405.dtsi:95 */
		timers7: timers@40001400 {
			compatible = "st,stm32-timers"; /* in zephyr/dts/arm/st/f4/stm32f405.dtsi:96 */
			reg = < 0x40001400 0x400 >;     /* in zephyr/dts/arm/st/f4/stm32f405.dtsi:97 */
			clocks = < &rcc 0x40 0x20 >,
			         < &rcc 0x15 0xff >;    /* in zephyr/dts/arm/st/f4/stm32f405.dtsi:98 */
			resets = < &rctl 0x405 >;       /* in zephyr/dts/arm/st/f4/stm32f405.dtsi:100 */
			interrupts = < 0x37 0x0 >;      /* in zephyr/dts/arm/st/f4/stm32f405.dtsi:101 */
			interrupt-names = "global";     /* in zephyr/dts/arm/st/f4/stm32f405.dtsi:102 */
			st,prescaler = < 0x0 >;         /* in zephyr/dts/arm/st/f4/stm32f405.dtsi:103 */
			status = "disabled";            /* in zephyr/dts/arm/st/f4/stm32f405.dtsi:104 */

			/* node '/soc/timers@40001400/counter' defined in zephyr/dts/arm/st/f4/stm32f405.dtsi:106 */
			counter {
				compatible = "st,stm32-counter"; /* in zephyr/dts/arm/st/f4/stm32f405.dtsi:107 */
				status = "disabled";             /* in zephyr/dts/arm/st/f4/stm32f405.dtsi:108 */
			};
		};

		/* node '/soc/timers@40010400' defined in zephyr/dts/arm/st/f4/stm32f405.dtsi:112 */
		timers8: timers@40010400 {
			compatible = "st,stm32-timers"; /* in zephyr/dts/arm/st/f4/stm32f405.dtsi:113 */
			reg = < 0x40010400 0x400 >;     /* in zephyr/dts/arm/st/f4/stm32f405.dtsi:114 */
			clocks = < &rcc 0x44 0x2 >,
			         < &rcc 0x16 0xff >;    /* in zephyr/dts/arm/st/f4/stm32f405.dtsi:115 */
			resets = < &rctl 0x481 >;       /* in zephyr/dts/arm/st/f4/stm32f405.dtsi:117 */
			interrupts = < 0x2b 0x0 >,
			             < 0x2c 0x0 >,
			             < 0x2d 0x0 >,
			             < 0x2e 0x0 >;      /* in zephyr/dts/arm/st/f4/stm32f405.dtsi:118 */
			interrupt-names = "brk",
			                  "up",
			                  "trgcom",
			                  "cc";         /* in zephyr/dts/arm/st/f4/stm32f405.dtsi:119 */
			st,prescaler = < 0x0 >;         /* in zephyr/dts/arm/st/f4/stm32f405.dtsi:120 */
			status = "disabled";            /* in zephyr/dts/arm/st/f4/stm32f405.dtsi:121 */

			/* node '/soc/timers@40010400/pwm' defined in zephyr/dts/arm/st/f4/stm32f405.dtsi:123 */
			pwm {
				compatible = "st,stm32-pwm"; /* in zephyr/dts/arm/st/f4/stm32f405.dtsi:124 */
				status = "disabled";         /* in zephyr/dts/arm/st/f4/stm32f405.dtsi:125 */
				#pwm-cells = < 0x3 >;        /* in zephyr/dts/arm/st/f4/stm32f405.dtsi:126 */
			};

			/* node '/soc/timers@40010400/counter' defined in zephyr/dts/arm/st/f4/stm32f405.dtsi:129 */
			counter {
				compatible = "st,stm32-counter"; /* in zephyr/dts/arm/st/f4/stm32f405.dtsi:130 */
				status = "disabled";             /* in zephyr/dts/arm/st/f4/stm32f405.dtsi:131 */
			};

			/* node '/soc/timers@40010400/qdec' defined in zephyr/dts/arm/st/f4/stm32f405.dtsi:134 */
			qdec {
				compatible = "st,stm32-qdec";    /* in zephyr/dts/arm/st/f4/stm32f405.dtsi:135 */
				st,input-filter-level = < 0x0 >; /* in zephyr/dts/arm/st/f4/stm32f405.dtsi:136 */
				status = "disabled";             /* in zephyr/dts/arm/st/f4/stm32f405.dtsi:137 */
			};
		};

		/* node '/soc/timers@40001800' defined in zephyr/dts/arm/st/f4/stm32f405.dtsi:141 */
		timers12: timers@40001800 {
			compatible = "st,stm32-timers"; /* in zephyr/dts/arm/st/f4/stm32f405.dtsi:142 */
			reg = < 0x40001800 0x400 >;     /* in zephyr/dts/arm/st/f4/stm32f405.dtsi:143 */
			clocks = < &rcc 0x40 0x40 >,
			         < &rcc 0x15 0xff >;    /* in zephyr/dts/arm/st/f4/stm32f405.dtsi:144 */
			resets = < &rctl 0x406 >;       /* in zephyr/dts/arm/st/f4/stm32f405.dtsi:146 */
			interrupts = < 0x2b 0x0 >;      /* in zephyr/dts/arm/st/f4/stm32f405.dtsi:147 */
			interrupt-names = "global";     /* in zephyr/dts/arm/st/f4/stm32f405.dtsi:148 */
			st,prescaler = < 0x0 >;         /* in zephyr/dts/arm/st/f4/stm32f405.dtsi:149 */
			status = "disabled";            /* in zephyr/dts/arm/st/f4/stm32f405.dtsi:150 */

			/* node '/soc/timers@40001800/pwm' defined in zephyr/dts/arm/st/f4/stm32f405.dtsi:152 */
			pwm {
				compatible = "st,stm32-pwm"; /* in zephyr/dts/arm/st/f4/stm32f405.dtsi:153 */
				status = "disabled";         /* in zephyr/dts/arm/st/f4/stm32f405.dtsi:154 */
				#pwm-cells = < 0x3 >;        /* in zephyr/dts/arm/st/f4/stm32f405.dtsi:155 */
			};

			/* node '/soc/timers@40001800/counter' defined in zephyr/dts/arm/st/f4/stm32f405.dtsi:158 */
			counter {
				compatible = "st,stm32-counter"; /* in zephyr/dts/arm/st/f4/stm32f405.dtsi:159 */
				status = "disabled";             /* in zephyr/dts/arm/st/f4/stm32f405.dtsi:160 */
			};
		};

		/* node '/soc/timers@40001c00' defined in zephyr/dts/arm/st/f4/stm32f405.dtsi:164 */
		timers13: timers@40001c00 {
			compatible = "st,stm32-timers"; /* in zephyr/dts/arm/st/f4/stm32f405.dtsi:165 */
			reg = < 0x40001c00 0x400 >;     /* in zephyr/dts/arm/st/f4/stm32f405.dtsi:166 */
			clocks = < &rcc 0x40 0x80 >,
			         < &rcc 0x15 0xff >;    /* in zephyr/dts/arm/st/f4/stm32f405.dtsi:167 */
			resets = < &rctl 0x407 >;       /* in zephyr/dts/arm/st/f4/stm32f405.dtsi:169 */
			interrupts = < 0x2c 0x0 >;      /* in zephyr/dts/arm/st/f4/stm32f405.dtsi:170 */
			interrupt-names = "global";     /* in zephyr/dts/arm/st/f4/stm32f405.dtsi:171 */
			st,prescaler = < 0x0 >;         /* in zephyr/dts/arm/st/f4/stm32f405.dtsi:172 */
			status = "disabled";            /* in zephyr/dts/arm/st/f4/stm32f405.dtsi:173 */

			/* node '/soc/timers@40001c00/pwm' defined in zephyr/dts/arm/st/f4/stm32f405.dtsi:175 */
			pwm {
				compatible = "st,stm32-pwm"; /* in zephyr/dts/arm/st/f4/stm32f405.dtsi:176 */
				status = "disabled";         /* in zephyr/dts/arm/st/f4/stm32f405.dtsi:177 */
				#pwm-cells = < 0x3 >;        /* in zephyr/dts/arm/st/f4/stm32f405.dtsi:178 */
			};

			/* node '/soc/timers@40001c00/counter' defined in zephyr/dts/arm/st/f4/stm32f405.dtsi:181 */
			counter {
				compatible = "st,stm32-counter"; /* in zephyr/dts/arm/st/f4/stm32f405.dtsi:182 */
				status = "disabled";             /* in zephyr/dts/arm/st/f4/stm32f405.dtsi:183 */
			};
		};

		/* node '/soc/timers@40002000' defined in zephyr/dts/arm/st/f4/stm32f405.dtsi:187 */
		timers14: timers@40002000 {
			compatible = "st,stm32-timers"; /* in zephyr/dts/arm/st/f4/stm32f405.dtsi:188 */
			reg = < 0x40002000 0x400 >;     /* in zephyr/dts/arm/st/f4/stm32f405.dtsi:189 */
			clocks = < &rcc 0x40 0x100 >,
			         < &rcc 0x15 0xff >;    /* in zephyr/dts/arm/st/f4/stm32f405.dtsi:190 */
			resets = < &rctl 0x408 >;       /* in zephyr/dts/arm/st/f4/stm32f405.dtsi:192 */
			interrupts = < 0x2d 0x0 >;      /* in zephyr/dts/arm/st/f4/stm32f405.dtsi:193 */
			interrupt-names = "global";     /* in zephyr/dts/arm/st/f4/stm32f405.dtsi:194 */
			st,prescaler = < 0x0 >;         /* in zephyr/dts/arm/st/f4/stm32f405.dtsi:195 */
			status = "disabled";            /* in zephyr/dts/arm/st/f4/stm32f405.dtsi:196 */

			/* node '/soc/timers@40002000/pwm' defined in zephyr/dts/arm/st/f4/stm32f405.dtsi:198 */
			pwm {
				compatible = "st,stm32-pwm"; /* in zephyr/dts/arm/st/f4/stm32f405.dtsi:199 */
				status = "disabled";         /* in zephyr/dts/arm/st/f4/stm32f405.dtsi:200 */
				#pwm-cells = < 0x3 >;        /* in zephyr/dts/arm/st/f4/stm32f405.dtsi:201 */
			};

			/* node '/soc/timers@40002000/counter' defined in zephyr/dts/arm/st/f4/stm32f405.dtsi:204 */
			counter {
				compatible = "st,stm32-counter"; /* in zephyr/dts/arm/st/f4/stm32f405.dtsi:205 */
				status = "disabled";             /* in zephyr/dts/arm/st/f4/stm32f405.dtsi:206 */
			};
		};

		/* node '/soc/usb@40040000' defined in zephyr/dts/arm/st/f4/stm32f405.dtsi:210 */
		usbotg_hs: usb@40040000 {
			compatible = "st,stm32-otghs";     /* in zephyr/dts/arm/st/f4/stm32f405.dtsi:211 */
			reg = < 0x40040000 0x40000 >;      /* in zephyr/dts/arm/st/f4/stm32f405.dtsi:212 */
			interrupts = < 0x4d 0x0 >,
			             < 0x4a 0x0 >,
			             < 0x4b 0x0 >;         /* in zephyr/dts/arm/st/f4/stm32f405.dtsi:213 */
			interrupt-names = "otghs",
			                  "ep1_out",
			                  "ep1_in";        /* in zephyr/dts/arm/st/f4/stm32f405.dtsi:214 */
			num-bidir-endpoints = < 0x6 >;     /* in zephyr/dts/arm/st/f4/stm32f405.dtsi:215 */
			ram-size = < 0x1000 >;             /* in zephyr/dts/arm/st/f4/stm32f405.dtsi:216 */
			maximum-speed = "full-speed";      /* in zephyr/dts/arm/st/f4/stm32f405.dtsi:217 */
			phys = < &otghs_fs_phy >;          /* in zephyr/dts/arm/st/f4/stm32f405.dtsi:218 */
			clocks = < &rcc 0x30 0x20000000 >,
			         < &rcc 0x7 0xff >;        /* in zephyr/dts/arm/st/f4/stm32f405.dtsi:219 */
			status = "disabled";               /* in zephyr/dts/arm/st/f4/stm32f405.dtsi:221 */
		};

		/* node '/soc/can@40006400' defined in zephyr/dts/arm/st/f4/stm32f405.dtsi:224 */
		can1: can@40006400 {
			compatible = "st,stm32-bxcan";    /* in zephyr/dts/arm/st/f4/stm32f405.dtsi:225 */
			reg = < 0x40006400 0x400 >;       /* in zephyr/dts/arm/st/f4/stm32f405.dtsi:226 */
			interrupts = < 0x13 0x0 >,
			             < 0x14 0x0 >,
			             < 0x15 0x0 >,
			             < 0x16 0x0 >;        /* in zephyr/dts/arm/st/f4/stm32f405.dtsi:227 */
			interrupt-names = "TX",
			                  "RX0",
			                  "RX1",
			                  "SCE";          /* in zephyr/dts/arm/st/f4/stm32f405.dtsi:228 */
			clocks = < &rcc 0x40 0x2000000 >; /* in zephyr/dts/arm/st/f4/stm32f405.dtsi:229 */
			status = "disabled";              /* in zephyr/dts/arm/st/f4/stm32f405.dtsi:230 */
		};

		/* node '/soc/can@40006800' defined in zephyr/dts/arm/st/f4/stm32f405.dtsi:233 */
		can2: can@40006800 {
			compatible = "st,stm32-bxcan";    /* in zephyr/dts/arm/st/f4/stm32f405.dtsi:234 */
			reg = < 0x40006800 0x400 >;       /* in zephyr/dts/arm/st/f4/stm32f405.dtsi:235 */
			interrupts = < 0x3f 0x0 >,
			             < 0x40 0x0 >,
			             < 0x41 0x0 >,
			             < 0x42 0x0 >;        /* in zephyr/dts/arm/st/f4/stm32f405.dtsi:236 */
			interrupt-names = "TX",
			                  "RX0",
			                  "RX1",
			                  "SCE";          /* in zephyr/dts/arm/st/f4/stm32f405.dtsi:237 */
			clocks = < &rcc 0x40 0x6000000 >; /* in zephyr/dts/arm/st/f4/stm32f405.dtsi:239 */
			master-can-reg = < 0x40006400 >;  /* in zephyr/dts/arm/st/f4/stm32f405.dtsi:240 */
			status = "disabled";              /* in zephyr/dts/arm/st/f4/stm32f405.dtsi:241 */
		};

		/* node '/soc/rng@50060800' defined in zephyr/dts/arm/st/f4/stm32f405.dtsi:244 */
		rng: rng@50060800 {
			compatible = "st,stm32-rng"; /* in zephyr/dts/arm/st/f4/stm32f405.dtsi:245 */
			reg = < 0x50060800 0x400 >;  /* in zephyr/dts/arm/st/f4/stm32f405.dtsi:246 */
			interrupts = < 0x50 0x0 >;   /* in zephyr/dts/arm/st/f4/stm32f405.dtsi:247 */
			clocks = < &rcc 0x34 0x40 >; /* in zephyr/dts/arm/st/f4/stm32f405.dtsi:248 */
			status = "okay";             /* in zephyr/boards/st/nucleo_f439zi/nucleo_f439zi.dts:179 */
		};

		/* node '/soc/memory@40024000' defined in zephyr/dts/arm/st/f4/stm32f405.dtsi:252 */
		backup_sram: memory@40024000 {
			compatible = "zephyr,memory-region",
			             "st,stm32-backup-sram";  /* in zephyr/dts/arm/st/f4/stm32f405.dtsi:253 */
			reg = < 0x40024000 0x1000 >;          /* in zephyr/dts/arm/st/f4/stm32f405.dtsi:254 */
			clocks = < &rcc 0x30 0x40000 >;       /* in zephyr/dts/arm/st/f4/stm32f405.dtsi:255 */
			zephyr,memory-region = "BACKUP_SRAM"; /* in zephyr/dts/arm/st/f4/stm32f405.dtsi:256 */
			status = "disabled";                  /* in zephyr/dts/arm/st/f4/stm32f405.dtsi:257 */
		};

		/* node '/soc/adc@40012100' defined in zephyr/dts/arm/st/f4/stm32f405.dtsi:260 */
		adc2: adc@40012100 {
			compatible = "st,stm32f4-adc",
			             "st,stm32-adc";                                 /* in zephyr/dts/arm/st/f4/stm32f405.dtsi:261 */
			reg = < 0x40012100 0x50 >;                                   /* in zephyr/dts/arm/st/f4/stm32f405.dtsi:262 */
			clocks = < &rcc 0x44 0x200 >;                                /* in zephyr/dts/arm/st/f4/stm32f405.dtsi:263 */
			clock-names = "adcx";                                        /* in zephyr/dts/arm/st/f4/stm32f405.dtsi:264 */
			interrupts = < 0x12 0x0 >;                                   /* in zephyr/dts/arm/st/f4/stm32f405.dtsi:265 */
			#io-channel-cells = < 0x1 >;                                 /* in zephyr/dts/arm/st/f4/stm32f405.dtsi:266 */
			st,adc-resolutions = < 0xc 0xa 0x8 0x6 >;                    /* in zephyr/dts/arm/st/f4/stm32f405.dtsi:267 */
			sampling-times = < 0x3 0xf 0x1c 0x38 0x54 0x70 0x90 0x1e0 >; /* in zephyr/dts/arm/st/f4/stm32f405.dtsi:268 */
			st,adc-clock-source = "SYNC";                                /* in zephyr/dts/arm/st/f4/stm32f405.dtsi:269 */
			st,adc-sequencer = "programmable";                           /* in zephyr/dts/arm/st/f4/stm32f405.dtsi:270 */
			st,adc-oversampler = "none";                                 /* in zephyr/dts/arm/st/f4/stm32f405.dtsi:271 */
			st,adc-internal-regulator = "none";                          /* in zephyr/dts/arm/st/f4/stm32f405.dtsi:272 */
			st,adc-has-injected-support;                                 /* in zephyr/dts/arm/st/f4/stm32f405.dtsi:273 */
			status = "disabled";                                         /* in zephyr/dts/arm/st/f4/stm32f405.dtsi:274 */
		};

		/* node '/soc/adc@40012200' defined in zephyr/dts/arm/st/f4/stm32f405.dtsi:277 */
		adc3: adc@40012200 {
			compatible = "st,stm32f4-adc",
			             "st,stm32-adc";                                 /* in zephyr/dts/arm/st/f4/stm32f405.dtsi:278 */
			reg = < 0x40012200 0x50 >;                                   /* in zephyr/dts/arm/st/f4/stm32f405.dtsi:279 */
			clocks = < &rcc 0x44 0x400 >;                                /* in zephyr/dts/arm/st/f4/stm32f405.dtsi:280 */
			clock-names = "adcx";                                        /* in zephyr/dts/arm/st/f4/stm32f405.dtsi:281 */
			interrupts = < 0x12 0x0 >;                                   /* in zephyr/dts/arm/st/f4/stm32f405.dtsi:282 */
			#io-channel-cells = < 0x1 >;                                 /* in zephyr/dts/arm/st/f4/stm32f405.dtsi:283 */
			st,adc-resolutions = < 0xc 0xa 0x8 0x6 >;                    /* in zephyr/dts/arm/st/f4/stm32f405.dtsi:284 */
			sampling-times = < 0x3 0xf 0x1c 0x38 0x54 0x70 0x90 0x1e0 >; /* in zephyr/dts/arm/st/f4/stm32f405.dtsi:285 */
			st,adc-clock-source = "SYNC";                                /* in zephyr/dts/arm/st/f4/stm32f405.dtsi:286 */
			st,adc-sequencer = "programmable";                           /* in zephyr/dts/arm/st/f4/stm32f405.dtsi:287 */
			st,adc-oversampler = "none";                                 /* in zephyr/dts/arm/st/f4/stm32f405.dtsi:288 */
			st,adc-internal-regulator = "none";                          /* in zephyr/dts/arm/st/f4/stm32f405.dtsi:289 */
			st,adc-has-injected-support;                                 /* in zephyr/dts/arm/st/f4/stm32f405.dtsi:290 */
			status = "disabled";                                         /* in zephyr/dts/arm/st/f4/stm32f405.dtsi:291 */
		};

		/* node '/soc/dac@40007400' defined in zephyr/dts/arm/st/f4/stm32f405.dtsi:294 */
		dac1: dac@40007400 {
			compatible = "st,stm32-dac";       /* in zephyr/dts/arm/st/f4/stm32f429.dtsi:15 */
			reg = < 0x40007400 0x400 >;        /* in zephyr/dts/arm/st/f4/stm32f429.dtsi:16 */
			clocks = < &rcc 0x40 0x20000000 >; /* in zephyr/dts/arm/st/f4/stm32f429.dtsi:17 */
			#io-channel-cells = < 0x1 >;       /* in zephyr/dts/arm/st/f4/stm32f429.dtsi:19 */
			status = "okay";                   /* in zephyr/boards/st/nucleo_f439zi/nucleo_f439zi.dts:107 */
			pinctrl-0 = < &dac_out1_pa4 >;     /* in zephyr/boards/st/nucleo_f439zi/nucleo_f439zi.dts:108 */
			pinctrl-names = "default";         /* in zephyr/boards/st/nucleo_f439zi/nucleo_f439zi.dts:109 */
		};

		/* node '/soc/ethernet@40028000' defined in zephyr/dts/arm/st/f4/stm32f407.dtsi:13 */
		mac: ethernet@40028000 {
			compatible = "st,stm32-ethernet",
			             "snps,dwmac";                                                                                /* in zephyr/dts/arm/st/f4/stm32f407.dtsi:14 */
			reg = < 0x40028000 0x8000 >;                                                                              /* in zephyr/dts/arm/st/f4/stm32f407.dtsi:15 */
			clock-names = "stm-eth",
			              "mac-clk-tx",
			              "mac-clk-rx",
			              "mac-clk-ptp";                                                                              /* in zephyr/dts/arm/st/f4/stm32f407.dtsi:16 */
			clocks = < &rcc 0x30 0x2000000 >,
			         < &rcc 0x30 0x4000000 >,
			         < &rcc 0x30 0x8000000 >,
			         < &rcc 0x30 0x10000000 >;                                                                        /* in zephyr/dts/arm/st/f4/stm32f407.dtsi:17 */
			interrupts = < 0x3d 0x0 >;                                                                                /* in zephyr/dts/arm/st/f4/stm32f407.dtsi:21 */
			status = "okay";                                                                                          /* in zephyr/boards/st/nucleo_f439zi/nucleo_f439zi.dts:187 */
			pinctrl-0 = < &eth_rxd0_pc4 &eth_rxd1_pc5 &eth_ref_clk_pa1 &eth_crs_dv_pa7 &eth_tx_en_pg11 &eth_txd0_pg13
			              &eth_txd1_pb13 >;                                                                           /* in zephyr/boards/st/nucleo_f439zi/nucleo_f439zi.dts:188 */
			pinctrl-names = "default";                                                                                /* in zephyr/boards/st/nucleo_f439zi/nucleo_f439zi.dts:195 */
			phy-connection-type = "rmii";                                                                             /* in zephyr/boards/st/nucleo_f439zi/nucleo_f439zi.dts:196 */
			phy-handle = < &eth_phy >;                                                                                /* in zephyr/boards/st/nucleo_f439zi/nucleo_f439zi.dts:197 */

			/* node '/soc/ethernet@40028000/mdio' defined in zephyr/dts/arm/st/f4/stm32f407.dtsi:24 */
			mdio: mdio {
				compatible = "snps,dwmac-mdio";             /* in zephyr/dts/arm/st/f4/stm32f407.dtsi:25 */
				#address-cells = < 0x1 >;                   /* in zephyr/dts/arm/st/f4/stm32f407.dtsi:26 */
				#size-cells = < 0x0 >;                      /* in zephyr/dts/arm/st/f4/stm32f407.dtsi:27 */
				status = "okay";                            /* in zephyr/boards/st/nucleo_f439zi/nucleo_f439zi.dts:201 */
				pinctrl-0 = < &eth_mdio_pa2 &eth_mdc_pc1 >; /* in zephyr/boards/st/nucleo_f439zi/nucleo_f439zi.dts:202 */
				pinctrl-names = "default";                  /* in zephyr/boards/st/nucleo_f439zi/nucleo_f439zi.dts:203 */

				/* node '/soc/ethernet@40028000/mdio/ethernet-phy@0' defined in zephyr/boards/st/nucleo_f439zi/nucleo_f439zi.dts:205 */
				eth_phy: ethernet-phy@0 {
					compatible = "ethernet-phy"; /* in zephyr/boards/st/nucleo_f439zi/nucleo_f439zi.dts:206 */
					reg = < 0x0 >;               /* in zephyr/boards/st/nucleo_f439zi/nucleo_f439zi.dts:207 */
					phandle = < 0x22 >;          /* in zephyr/boards/st/nucleo_f439zi/nucleo_f439zi.dts:197 */
				};
			};

			/* node '/soc/ethernet@40028000/ptp-clock' defined in zephyr/dts/arm/st/f4/stm32f407.dtsi:31 */
			ptp_clock: ptp-clock {
				compatible = "snps,dwmac-ptp-clock"; /* in zephyr/dts/arm/st/f4/stm32f407.dtsi:32 */
			};
		};

		/* node '/soc/serial@40007800' defined in zephyr/dts/arm/st/f4/stm32f427.dtsi:48 */
		uart7: serial@40007800 {
			compatible = "st,stm32-uart";      /* in zephyr/dts/arm/st/f4/stm32f427.dtsi:49 */
			reg = < 0x40007800 0x400 >;        /* in zephyr/dts/arm/st/f4/stm32f427.dtsi:50 */
			clocks = < &rcc 0x40 0x40000000 >; /* in zephyr/dts/arm/st/f4/stm32f427.dtsi:51 */
			resets = < &rctl 0x41e >;          /* in zephyr/dts/arm/st/f4/stm32f427.dtsi:52 */
			interrupts = < 0x52 0x0 >;         /* in zephyr/dts/arm/st/f4/stm32f427.dtsi:53 */
			status = "disabled";               /* in zephyr/dts/arm/st/f4/stm32f427.dtsi:54 */
		};

		/* node '/soc/serial@40007c00' defined in zephyr/dts/arm/st/f4/stm32f427.dtsi:57 */
		uart8: serial@40007c00 {
			compatible = "st,stm32-uart";      /* in zephyr/dts/arm/st/f4/stm32f427.dtsi:58 */
			reg = < 0x40007c00 0x400 >;        /* in zephyr/dts/arm/st/f4/stm32f427.dtsi:59 */
			clocks = < &rcc 0x40 0x80000000 >; /* in zephyr/dts/arm/st/f4/stm32f427.dtsi:60 */
			resets = < &rctl 0x41f >;          /* in zephyr/dts/arm/st/f4/stm32f427.dtsi:61 */
			interrupts = < 0x53 0x0 >;         /* in zephyr/dts/arm/st/f4/stm32f427.dtsi:62 */
			status = "disabled";               /* in zephyr/dts/arm/st/f4/stm32f427.dtsi:63 */
		};

		/* node '/soc/spi@40015000' defined in zephyr/dts/arm/st/f4/stm32f427.dtsi:80 */
		spi5: spi@40015000 {
			compatible = "st,stm32-spi";            /* in zephyr/dts/arm/st/f4/stm32f427.dtsi:81 */
			#address-cells = < 0x1 >;               /* in zephyr/dts/arm/st/f4/stm32f427.dtsi:82 */
			#size-cells = < 0x0 >;                  /* in zephyr/dts/arm/st/f4/stm32f427.dtsi:83 */
			reg = < 0x40015000 0x400 >;             /* in zephyr/dts/arm/st/f4/stm32f427.dtsi:84 */
			clocks = < &rcc 0x44 0x100000 >;        /* in zephyr/dts/arm/st/f4/stm32f427.dtsi:85 */
			interrupts = < 0x55 0x0 >;              /* in zephyr/dts/arm/st/f4/stm32f427.dtsi:86 */
			st,spi-data-width = "limited-8-16-bit"; /* in zephyr/dts/arm/st/f4/stm32f427.dtsi:87 */
			status = "disabled";                    /* in zephyr/dts/arm/st/f4/stm32f427.dtsi:88 */
		};

		/* node '/soc/spi@40015400' defined in zephyr/dts/arm/st/f4/stm32f427.dtsi:94 */
		spi6: spi@40015400 {
			compatible = "st,stm32-spi";            /* in zephyr/dts/arm/st/f4/stm32f427.dtsi:95 */
			#address-cells = < 0x1 >;               /* in zephyr/dts/arm/st/f4/stm32f427.dtsi:96 */
			#size-cells = < 0x0 >;                  /* in zephyr/dts/arm/st/f4/stm32f427.dtsi:97 */
			reg = < 0x40015400 0x400 >;             /* in zephyr/dts/arm/st/f4/stm32f427.dtsi:98 */
			clocks = < &rcc 0x44 0x200000 >;        /* in zephyr/dts/arm/st/f4/stm32f427.dtsi:99 */
			interrupts = < 0x56 0x0 >;              /* in zephyr/dts/arm/st/f4/stm32f427.dtsi:100 */
			st,spi-data-width = "limited-8-16-bit"; /* in zephyr/dts/arm/st/f4/stm32f427.dtsi:101 */
			status = "disabled";                    /* in zephyr/dts/arm/st/f4/stm32f427.dtsi:102 */
		};

		/* node '/soc/memory-controller@a0000000' defined in zephyr/dts/arm/st/f4/stm32f427.dtsi:105 */
		fmc: memory-controller@a0000000 {
			compatible = "st,stm32-fmc"; /* in zephyr/dts/arm/st/f4/stm32f427.dtsi:106 */
			reg = < 0xa0000000 0x400 >;  /* in zephyr/dts/arm/st/f4/stm32f427.dtsi:107 */
			clocks = < &rcc 0x38 0x1 >;  /* in zephyr/dts/arm/st/f4/stm32f427.dtsi:108 */
			status = "disabled";         /* in zephyr/dts/arm/st/f4/stm32f427.dtsi:109 */

			/* node '/soc/memory-controller@a0000000/sdram' defined in zephyr/dts/arm/st/f4/stm32f427.dtsi:111 */
			sdram: sdram {
				compatible = "st,stm32-fmc-sdram"; /* in zephyr/dts/arm/st/f4/stm32f427.dtsi:112 */
				#address-cells = < 0x1 >;          /* in zephyr/dts/arm/st/f4/stm32f427.dtsi:113 */
				#size-cells = < 0x0 >;             /* in zephyr/dts/arm/st/f4/stm32f427.dtsi:114 */
				status = "disabled";               /* in zephyr/dts/arm/st/f4/stm32f427.dtsi:115 */
			};
		};

		/* node '/soc/sai1@40015800' defined in zephyr/dts/arm/st/f4/stm32f427.dtsi:119 */
		sai1: sai1@40015800 {
			compatible = "st,stm32-sai";     /* in zephyr/dts/arm/st/f4/stm32f427.dtsi:120 */
			#address-cells = < 0x1 >;        /* in zephyr/dts/arm/st/f4/stm32f427.dtsi:121 */
			#size-cells = < 0x1 >;           /* in zephyr/dts/arm/st/f4/stm32f427.dtsi:122 */
			reg = < 0x40015800 0x400 >;      /* in zephyr/dts/arm/st/f4/stm32f427.dtsi:123 */
			ranges;                          /* in zephyr/dts/arm/st/f4/stm32f427.dtsi:124 */
			clocks = < &rcc 0x44 0x400000 >; /* in zephyr/dts/arm/st/f4/stm32f427.dtsi:125 */
			clock-names = "sai_ck";          /* in zephyr/dts/arm/st/f4/stm32f427.dtsi:126 */
			status = "disabled";             /* in zephyr/dts/arm/st/f4/stm32f427.dtsi:127 */

			/* node '/soc/sai1@40015800/sai1a@40015804' defined in zephyr/dts/arm/st/f4/stm32f427.dtsi:129 */
			sai1_a: sai1a@40015804 {
				reg = < 0x40015804 0x20 >;            /* in zephyr/dts/arm/st/f4/stm32f427.dtsi:130 */
				dmas = < &dma2 0x1 0x0 0x22800 0x0 >; /* in zephyr/dts/arm/st/f4/stm32f427.dtsi:131 */
				#address-cells = < 0x1 >;             /* in zephyr/dts/arm/st/f4/stm32f427.dtsi:132 */
				#size-cells = < 0x0 >;                /* in zephyr/dts/arm/st/f4/stm32f427.dtsi:133 */
				status = "disabled";                  /* in zephyr/dts/arm/st/f4/stm32f427.dtsi:134 */
			};

			/* node '/soc/sai1@40015800/sai1b@40015824' defined in zephyr/dts/arm/st/f4/stm32f427.dtsi:137 */
			sai1_b: sai1b@40015824 {
				reg = < 0x40015824 0x20 >;            /* in zephyr/dts/arm/st/f4/stm32f427.dtsi:138 */
				dmas = < &dma2 0x5 0x0 0x22800 0x0 >; /* in zephyr/dts/arm/st/f4/stm32f427.dtsi:139 */
				#address-cells = < 0x1 >;             /* in zephyr/dts/arm/st/f4/stm32f427.dtsi:140 */
				#size-cells = < 0x0 >;                /* in zephyr/dts/arm/st/f4/stm32f427.dtsi:141 */
				status = "disabled";                  /* in zephyr/dts/arm/st/f4/stm32f427.dtsi:142 */
			};
		};

		/* node '/soc/display-controller@40016800' defined in zephyr/dts/arm/st/f4/stm32f429.dtsi:22 */
		ltdc: display-controller@40016800 {
			compatible = "st,stm32-ltdc";     /* in zephyr/dts/arm/st/f4/stm32f429.dtsi:23 */
			reg = < 0x40016800 0x200 >;       /* in zephyr/dts/arm/st/f4/stm32f429.dtsi:24 */
			interrupts = < 0x58 0x0 >,
			             < 0x59 0x0 >;        /* in zephyr/dts/arm/st/f4/stm32f429.dtsi:25 */
			interrupt-names = "ltdc",
			                  "ltdc_er";      /* in zephyr/dts/arm/st/f4/stm32f429.dtsi:26 */
			clocks = < &rcc 0x44 0x4000000 >; /* in zephyr/dts/arm/st/f4/stm32f429.dtsi:27 */
			resets = < &rctl 0x49a >;         /* in zephyr/dts/arm/st/f4/stm32f429.dtsi:28 */
			status = "disabled";              /* in zephyr/dts/arm/st/f4/stm32f429.dtsi:29 */
		};

		/* node '/soc/crypto@50060000' defined in zephyr/dts/arm/st/f4/stm32f439.dtsi:13 */
		cryp: crypto@50060000 {
			compatible = "st,stm32-cryp"; /* in zephyr/dts/arm/st/f4/stm32f439.dtsi:14 */
			reg = < 0x50060000 0x400 >;   /* in zephyr/dts/arm/st/f4/stm32f439.dtsi:15 */
			clocks = < &rcc 0x34 0x10 >;  /* in zephyr/dts/arm/st/f4/stm32f439.dtsi:16 */
			resets = < &rctl 0x284 >;     /* in zephyr/dts/arm/st/f4/stm32f439.dtsi:17 */
			interrupts = < 0x4f 0x0 >;    /* in zephyr/dts/arm/st/f4/stm32f439.dtsi:18 */
			status = "disabled";          /* in zephyr/dts/arm/st/f4/stm32f439.dtsi:19 */
		};
	};

	/* node '/cpus' defined in zephyr/dts/arm/st/f4/stm32f4.dtsi:30 */
	cpus {
		#address-cells = < 0x1 >; /* in zephyr/dts/arm/st/f4/stm32f4.dtsi:31 */
		#size-cells = < 0x0 >;    /* in zephyr/dts/arm/st/f4/stm32f4.dtsi:32 */

		/* node '/cpus/cpu@0' defined in zephyr/dts/arm/st/f4/stm32f4.dtsi:34 */
		cpu0: cpu@0 {
			device_type = "cpu";           /* in zephyr/dts/arm/st/f4/stm32f4.dtsi:35 */
			compatible = "arm,cortex-m4f"; /* in zephyr/dts/arm/st/f4/stm32f4.dtsi:36 */
			reg = < 0x0 >;                 /* in zephyr/dts/arm/st/f4/stm32f4.dtsi:37 */
			cpu-power-states = < &stop >;  /* in zephyr/dts/arm/st/f4/stm32f4.dtsi:38 */
		};

		/* node '/cpus/power-states' defined in zephyr/dts/arm/st/f4/stm32f4.dtsi:41 */
		power-states {

			/* node '/cpus/power-states/stop' defined in zephyr/dts/arm/st/f4/stm32f4.dtsi:42 */
			stop: stop {
				compatible = "zephyr,power-state";    /* in zephyr/dts/arm/st/f4/stm32f4.dtsi:43 */
				power-state-name = "suspend-to-idle"; /* in zephyr/dts/arm/st/f4/stm32f4.dtsi:44 */
				min-residency-us = < 0x190 >;         /* in zephyr/dts/arm/st/f4/stm32f4.dtsi:51 */
				exit-latency-us = < 0x12c >;          /* in zephyr/dts/arm/st/f4/stm32f4.dtsi:52 */
				phandle = < 0x26 >;                   /* in zephyr/dts/arm/st/f4/stm32f4.dtsi:38 */
			};
		};
	};

	/* node '/memory@20000000' defined in zephyr/dts/arm/st/f4/stm32f4.dtsi:57 */
	sram0: memory@20000000 {
		compatible = "zephyr,memory-region",
		             "mmio-sram";            /* in zephyr/dts/arm/st/f4/stm32f4.dtsi:58 */
		zephyr,memory-region = "SRAM0";      /* in zephyr/dts/arm/st/f4/stm32f4.dtsi:59 */
		reg = < 0x20000000 0x30000 >;        /* in zephyr/dts/arm/st/f4/stm32f439Xi.dtsi:17 */
	};

	/* node '/clocks' defined in zephyr/dts/arm/st/f4/stm32f4.dtsi:62 */
	clocks {

		/* node '/clocks/clk-hse' defined in zephyr/dts/arm/st/f4/stm32f4.dtsi:63 */
		clk_hse: clk-hse {
			#clock-cells = < 0x0 >;            /* in zephyr/dts/arm/st/f4/stm32f4.dtsi:64 */
			compatible = "st,stm32-hse-clock"; /* in zephyr/dts/arm/st/f4/stm32f4.dtsi:65 */
			hse-bypass;                        /* in zephyr/boards/st/nucleo_f439zi/nucleo_f439zi.dts:72 */
			clock-frequency = < 0x7a1200 >;    /* in zephyr/boards/st/nucleo_f439zi/nucleo_f439zi.dts:73 */
			status = "okay";                   /* in zephyr/boards/st/nucleo_f439zi/nucleo_f439zi.dts:74 */
			phandle = < 0x27 >;                /* in zephyr/boards/st/nucleo_f439zi/nucleo_f439zi.dts:82 */
		};

		/* node '/clocks/clk-hsi' defined in zephyr/dts/arm/st/f4/stm32f4.dtsi:69 */
		clk_hsi: clk-hsi {
			#clock-cells = < 0x0 >;         /* in zephyr/dts/arm/st/f4/stm32f4.dtsi:70 */
			compatible = "fixed-clock";     /* in zephyr/dts/arm/st/f4/stm32f4.dtsi:71 */
			clock-frequency = < 0xf42400 >; /* in zephyr/dts/arm/st/f4/stm32f4.dtsi:72 */
			status = "disabled";            /* in zephyr/dts/arm/st/f4/stm32f4.dtsi:73 */
		};

		/* node '/clocks/clk-lse' defined in zephyr/dts/arm/st/f4/stm32f4.dtsi:76 */
		clk_lse: clk-lse {
			#clock-cells = < 0x0 >;       /* in zephyr/dts/arm/st/f4/stm32f4.dtsi:77 */
			compatible = "fixed-clock";   /* in zephyr/dts/arm/st/f4/stm32f4.dtsi:78 */
			clock-frequency = < 0x8000 >; /* in zephyr/dts/arm/st/f4/stm32f4.dtsi:79 */
			status = "disabled";          /* in zephyr/dts/arm/st/f4/stm32f4.dtsi:80 */
		};

		/* node '/clocks/clk-lsi' defined in zephyr/dts/arm/st/f4/stm32f4.dtsi:83 */
		clk_lsi: clk-lsi {
			#clock-cells = < 0x0 >;       /* in zephyr/dts/arm/st/f4/stm32f4.dtsi:84 */
			compatible = "fixed-clock";   /* in zephyr/dts/arm/st/f4/stm32f4.dtsi:85 */
			clock-frequency = < 0x7d00 >; /* in zephyr/dts/arm/st/f4/stm32f4.dtsi:86 */
			status = "okay";              /* in zephyr/boards/st/nucleo_f439zi/nucleo_f439zi.dts:68 */
		};

		/* node '/clocks/pll' defined in zephyr/dts/arm/st/f4/stm32f4.dtsi:90 */
		pll: pll {
			#clock-cells = < 0x0 >;              /* in zephyr/dts/arm/st/f4/stm32f4.dtsi:91 */
			compatible = "st,stm32fx-pll-clock"; /* in zephyr/dts/arm/st/f4/stm32f4.dtsi:92 */
			div-m = < 0x8 >;                     /* in zephyr/boards/st/nucleo_f439zi/nucleo_f439zi.dts:78 */
			mul-n = < 0x150 >;                   /* in zephyr/boards/st/nucleo_f439zi/nucleo_f439zi.dts:79 */
			div-p = < 0x2 >;                     /* in zephyr/boards/st/nucleo_f439zi/nucleo_f439zi.dts:80 */
			div-q = < 0x7 >;                     /* in zephyr/boards/st/nucleo_f439zi/nucleo_f439zi.dts:81 */
			clocks = < &clk_hse >;               /* in zephyr/boards/st/nucleo_f439zi/nucleo_f439zi.dts:82 */
			status = "okay";                     /* in zephyr/boards/st/nucleo_f439zi/nucleo_f439zi.dts:83 */
			phandle = < 0x2 >;                   /* in zephyr/boards/st/nucleo_f439zi/nucleo_f439zi.dts:87 */
		};

		/* node '/clocks/plli2s' defined in zephyr/dts/arm/st/f4/stm32f401.dtsi:11 */
		plli2s: plli2s {
			#clock-cells = < 0x0 >;              /* in zephyr/dts/arm/st/f4/stm32f401.dtsi:12 */
			compatible = "st,stm32fx-pll-clock"; /* in zephyr/dts/arm/st/f4/stm32f401.dtsi:13 */
			status = "disabled";                 /* in zephyr/dts/arm/st/f4/stm32f401.dtsi:14 */
		};

		/* node '/clocks/pllsai' defined in zephyr/dts/arm/st/f4/stm32f427.dtsi:14 */
		pllsai: pllsai {
			compatible = "st,stm32fx-pll-clock"; /* in zephyr/dts/arm/st/f4/stm32f427.dtsi:15 */
			#clock-cells = < 0x0 >;              /* in zephyr/dts/arm/st/f4/stm32f427.dtsi:16 */
			status = "disabled";                 /* in zephyr/dts/arm/st/f4/stm32f427.dtsi:17 */
		};
	};

	/* node '/mcos' defined in zephyr/dts/arm/st/f4/stm32f4.dtsi:97 */
	mcos {

		/* node '/mcos/mco1' defined in zephyr/dts/arm/st/f4/stm32f4.dtsi:98 */
		mco1: mco1 {
			compatible = "st,stm32-clock-mco"; /* in zephyr/dts/arm/st/f4/stm32f4.dtsi:99 */
			clock-names = "clksel";            /* in zephyr/dts/arm/st/f4/stm32f4.dtsi:100 */
			status = "disabled";               /* in zephyr/dts/arm/st/f4/stm32f4.dtsi:101 */
		};

		/* node '/mcos/mco2' defined in zephyr/dts/arm/st/f4/stm32f4.dtsi:104 */
		mco2: mco2 {
			compatible = "st,stm32-clock-mco"; /* in zephyr/dts/arm/st/f4/stm32f4.dtsi:105 */
			clock-names = "clksel";            /* in zephyr/dts/arm/st/f4/stm32f4.dtsi:106 */
			status = "disabled";               /* in zephyr/dts/arm/st/f4/stm32f4.dtsi:107 */
		};
	};

	/* node '/dietemp' defined in zephyr/dts/arm/st/f4/stm32f4.dtsi:676 */
	die_temp: dietemp {
		compatible = "st,stm32-temp-cal"; /* in zephyr/dts/arm/st/f4/stm32f4.dtsi:677 */
		nvmem-cells = < &ts_cal1_otp >,
		              < &ts_cal2_otp >;   /* in zephyr/dts/arm/st/f4/stm32f4.dtsi:678 */
		nvmem-cell-names = "TS_CAL1",
		                   "TS_CAL2";     /* in zephyr/dts/arm/st/f4/stm32f4.dtsi:679 */
		ts-cal1-temp = < 0x1e >;          /* in zephyr/dts/arm/st/f4/stm32f4.dtsi:680 */
		ts-cal2-temp = < 0x6e >;          /* in zephyr/dts/arm/st/f4/stm32f4.dtsi:681 */
		ts-cal-vrefanalog = < 0xce4 >;    /* in zephyr/dts/arm/st/f4/stm32f4.dtsi:682 */
		io-channels = < &adc1 0x12 >;     /* in zephyr/dts/arm/st/f4/stm32f427.dtsi:148 */
		status = "okay";                  /* in zephyr/boards/st/nucleo_f439zi/nucleo_f439zi.dts:103 */
	};

	/* node '/vref' defined in zephyr/dts/arm/st/f4/stm32f4.dtsi:687 */
	vref: vref {
		compatible = "st,stm32-vref";   /* in zephyr/dts/arm/st/f4/stm32f4.dtsi:688 */
		nvmem-cells = < &vrefint_otp >; /* in zephyr/dts/arm/st/f4/stm32f4.dtsi:689 */
		vrefint-cal-mv = < 0xce4 >;     /* in zephyr/dts/arm/st/f4/stm32f4.dtsi:690 */
		io-channels = < &adc1 0x11 >;   /* in zephyr/dts/arm/st/f4/stm32f4.dtsi:691 */
		status = "okay";                /* in zephyr/boards/st/nucleo_f439zi/nucleo_f439zi.dts:282 */
	};

	/* node '/vbat' defined in zephyr/dts/arm/st/f4/stm32f4.dtsi:695 */
	vbat: vbat {
		compatible = "st,stm32-vbat"; /* in zephyr/dts/arm/st/f4/stm32f4.dtsi:696 */
		ratio = < 0x4 >;              /* in zephyr/dts/arm/st/f4/stm32f4.dtsi:697 */
		io-channels = < &adc1 0x12 >; /* in zephyr/dts/arm/st/f4/stm32f4.dtsi:698 */
		status = "okay";              /* in zephyr/boards/st/nucleo_f439zi/nucleo_f439zi.dts:286 */
	};

	/* node '/otgfs_phy' defined in zephyr/dts/arm/st/f4/stm32f4.dtsi:702 */
	otgfs_phy: otgfs_phy {
		compatible = "usb-nop-xceiv"; /* in zephyr/dts/arm/st/f4/stm32f4.dtsi:703 */
		#phy-cells = < 0x0 >;         /* in zephyr/dts/arm/st/f4/stm32f4.dtsi:704 */
		phandle = < 0x10 >;           /* in zephyr/dts/arm/st/f4/stm32f4.dtsi:373 */
	};

	/* node '/smbus1' defined in zephyr/dts/arm/st/f4/stm32f4.dtsi:707 */
	smbus1: smbus1 {
		compatible = "st,stm32-smbus"; /* in zephyr/dts/arm/st/f4/stm32f4.dtsi:708 */
		#address-cells = < 0x1 >;      /* in zephyr/dts/arm/st/f4/stm32f4.dtsi:709 */
		#size-cells = < 0x0 >;         /* in zephyr/dts/arm/st/f4/stm32f4.dtsi:710 */
		i2c = < &i2c1 >;               /* in zephyr/dts/arm/st/f4/stm32f4.dtsi:711 */
		status = "disabled";           /* in zephyr/dts/arm/st/f4/stm32f4.dtsi:712 */
	};

	/* node '/smbus2' defined in zephyr/dts/arm/st/f4/stm32f4.dtsi:715 */
	smbus2: smbus2 {
		compatible = "st,stm32-smbus"; /* in zephyr/dts/arm/st/f4/stm32f4.dtsi:716 */
		#address-cells = < 0x1 >;      /* in zephyr/dts/arm/st/f4/stm32f4.dtsi:717 */
		#size-cells = < 0x0 >;         /* in zephyr/dts/arm/st/f4/stm32f4.dtsi:718 */
		i2c = < &i2c2 >;               /* in zephyr/dts/arm/st/f4/stm32f4.dtsi:719 */
		status = "disabled";           /* in zephyr/dts/arm/st/f4/stm32f4.dtsi:720 */
	};

	/* node '/smbus3' defined in zephyr/dts/arm/st/f4/stm32f4.dtsi:723 */
	smbus3: smbus3 {
		compatible = "st,stm32-smbus"; /* in zephyr/dts/arm/st/f4/stm32f4.dtsi:724 */
		#address-cells = < 0x1 >;      /* in zephyr/dts/arm/st/f4/stm32f4.dtsi:725 */
		#size-cells = < 0x0 >;         /* in zephyr/dts/arm/st/f4/stm32f4.dtsi:726 */
		i2c = < &i2c3 >;               /* in zephyr/dts/arm/st/f4/stm32f4.dtsi:727 */
		status = "disabled";           /* in zephyr/dts/arm/st/f4/stm32f4.dtsi:728 */
	};

	/* node '/otghs_fs_phy' defined in zephyr/dts/arm/st/f4/stm32f405.dtsi:303 */
	otghs_fs_phy: otghs_fs_phy {
		compatible = "usb-nop-xceiv"; /* in zephyr/dts/arm/st/f4/stm32f405.dtsi:304 */
		#phy-cells = < 0x0 >;         /* in zephyr/dts/arm/st/f4/stm32f405.dtsi:305 */
		phandle = < 0x19 >;           /* in zephyr/dts/arm/st/f4/stm32f405.dtsi:218 */
	};

	/* node '/memory@10000000' defined in zephyr/dts/arm/st/f4/stm32f439Xi.dtsi:10 */
	ccm0: memory@10000000 {
		compatible = "zephyr,memory-region",
		             "st,stm32-ccm";         /* in zephyr/dts/arm/st/f4/stm32f439Xi.dtsi:11 */
		reg = < 0x10000000 0x10000 >;        /* in zephyr/dts/arm/st/f4/stm32f439Xi.dtsi:12 */
		zephyr,memory-region = "DTCM";       /* in zephyr/dts/arm/st/f4/stm32f439Xi.dtsi:13 */
	};

	/* node '/connector' defined in zephyr/boards/st/nucleo_f439zi/arduino_r3_connector.dtsi:10 */
	arduino_header: connector {
		compatible = "arduino-header-r3";          /* in zephyr/boards/st/nucleo_f439zi/arduino_r3_connector.dtsi:11 */
		#gpio-cells = < 0x2 >;                     /* in zephyr/boards/st/nucleo_f439zi/arduino_r3_connector.dtsi:12 */
		gpio-map-mask = < 0xffffffff 0xffffffc0 >; /* in zephyr/boards/st/nucleo_f439zi/arduino_r3_connector.dtsi:13 */
		gpio-map-pass-thru = < 0x0 0x3f >;         /* in zephyr/boards/st/nucleo_f439zi/arduino_r3_connector.dtsi:14 */
		gpio-map = < 0x0 0x0 &gpioa 0x3 0x0 >,
		           < 0x1 0x0 &gpioc 0x0 0x0 >,
		           < 0x2 0x0 &gpioc 0x3 0x0 >,
		           < 0x3 0x0 &gpiof 0x3 0x0 >,
		           < 0x4 0x0 &gpiof 0x5 0x0 >,
		           < 0x5 0x0 &gpiof 0xa 0x0 >,
		           < 0x6 0x0 &gpiog 0x9 0x0 >,
		           < 0x7 0x0 &gpiog 0xe 0x0 >,
		           < 0x8 0x0 &gpiof 0xf 0x0 >,
		           < 0x9 0x0 &gpioe 0xd 0x0 >,
		           < 0xa 0x0 &gpiof 0xe 0x0 >,
		           < 0xb 0x0 &gpioe 0xb 0x0 >,
		           < 0xc 0x0 &gpioe 0x9 0x0 >,
		           < 0xd 0x0 &gpiof 0xd 0x0 >,
		           < 0xe 0x0 &gpiof 0xc 0x0 >,
		           < 0xf 0x0 &gpiod 0xf 0x0 >,
		           < 0x10 0x0 &gpiod 0xe 0x0 >,
		           < 0x11 0x0 &gpioa 0x7 0x0 >,
		           < 0x12 0x0 &gpioa 0x6 0x0 >,
		           < 0x13 0x0 &gpioa 0x5 0x0 >,
		           < 0x14 0x0 &gpiob 0x9 0x0 >,
		           < 0x15 0x0 &gpiob 0x8 0x0 >;    /* in zephyr/boards/st/nucleo_f439zi/arduino_r3_connector.dtsi:15 */
	};

	/* node '/leds' defined in zephyr/boards/st/nucleo_f439zi/nucleo_f439zi.dts:26 */
	leds: leds {
		compatible = "gpio-leds"; /* in zephyr/boards/st/nucleo_f439zi/nucleo_f439zi.dts:27 */

		/* node '/leds/led_1' defined in zephyr/boards/st/nucleo_f439zi/nucleo_f439zi.dts:29 */
		green_led_1: led_1 {
			gpios = < &gpiob 0x0 0x0 >; /* in zephyr/boards/st/nucleo_f439zi/nucleo_f439zi.dts:30 */
			label = "User LD1";         /* in zephyr/boards/st/nucleo_f439zi/nucleo_f439zi.dts:31 */
		};

		/* node '/leds/led_2' defined in zephyr/boards/st/nucleo_f439zi/nucleo_f439zi.dts:34 */
		blue_led_1: led_2 {
			gpios = < &gpiob 0x7 0x0 >; /* in zephyr/boards/st/nucleo_f439zi/nucleo_f439zi.dts:35 */
			label = "User LD2";         /* in zephyr/boards/st/nucleo_f439zi/nucleo_f439zi.dts:36 */
		};

		/* node '/leds/led_3' defined in zephyr/boards/st/nucleo_f439zi/nucleo_f439zi.dts:39 */
		red_led_1: led_3 {
			gpios = < &gpiob 0xe 0x0 >; /* in zephyr/boards/st/nucleo_f439zi/nucleo_f439zi.dts:40 */
			label = "User LD3";         /* in zephyr/boards/st/nucleo_f439zi/nucleo_f439zi.dts:41 */
		};
	};

	/* node '/gpio_keys' defined in zephyr/boards/st/nucleo_f439zi/nucleo_f439zi.dts:45 */
	gpio_keys {
		compatible = "gpio-keys"; /* in zephyr/boards/st/nucleo_f439zi/nucleo_f439zi.dts:46 */

		/* node '/gpio_keys/button' defined in zephyr/boards/st/nucleo_f439zi/nucleo_f439zi.dts:48 */
		user_button: button {
			label = "User";             /* in zephyr/boards/st/nucleo_f439zi/nucleo_f439zi.dts:49 */
			gpios = < &gpioc 0xd 0x0 >; /* in zephyr/boards/st/nucleo_f439zi/nucleo_f439zi.dts:50 */
			zephyr,code = < 0xb >;      /* in zephyr/boards/st/nucleo_f439zi/nucleo_f439zi.dts:51 */
		};
	};
};
